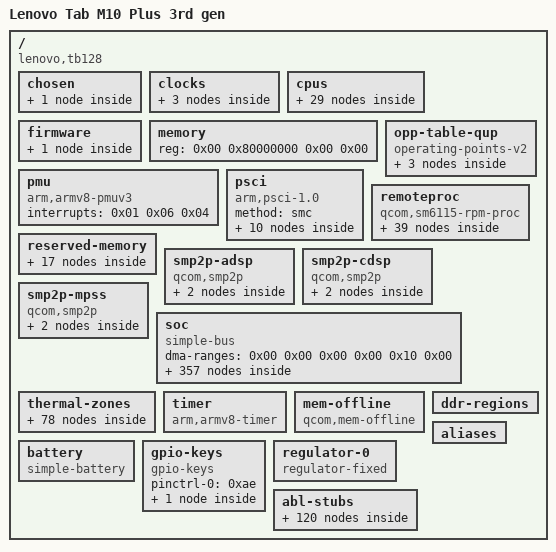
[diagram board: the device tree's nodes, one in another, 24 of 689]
/dts-v1/;

/ {
	interrupt-parent = <0x01>;
	#address-cells = <0x02>;
	#size-cells = <0x02>;
	model = "Lenovo Tab M10 Plus 3rd gen";
	compatible = "lenovo,tb128\0qcom,sm6225\0qcom,sm6115";
	chassis-type = "tablet";
	qcom,msm-id = <0x206 0x10000>;
	qcom,board-id = <0x10022 0x00>;
	qcom,pmic-id = <0x2d 0x00 0x00 0x00>;

	chosen {
		linux,initrd-start = <0x00 0x44986000>;
		linux,initrd-end = <0x00 0x456fe3fc>;
		kaslr-seed = <0x00 0x00>;
		bootargs = "root=/dev/sda18 rw rootwait noinitrd init=/sbin/init console=tty0 PMOS_NOSPLASH";
		#address-cells = <0x02>;
		#size-cells = <0x02>;
		ranges;
		stdout-path = "serial0:115200n8";

		framebuffer@5c000000 {
			compatible = "simple-framebuffer";
			reg = <0x00 0x5c000000 0x00 0x927c00>;
			width = <0x4b0>;
			height = <0x7d0>;
			stride = <0x12c0>;
			format = "a8r8g8b8";
			clocks = <0x02 0x4c>;
		};
	};

	clocks {

		xo-board {
			compatible = "fixed-clock";
			#clock-cells = <0x00>;
			clock-frequency = <0x124f800>;
			phandle = <0x25>;
		};

		sleep-clk {
			compatible = "fixed-clock";
			#clock-cells = <0x00>;
			clock-frequency = <0x7ffc>;
			phandle = <0x2c>;
		};

		usb3_phy_wrapper_gcc_usb30_pipe_clk {
			compatible = "fixed-clock";
			#clock-cells = <0x00>;
			clock-frequency = <0x3e8>;
			clock-output-names = "usb3_phy_wrapper_gcc_usb30_pipe_clk";
		};
	};

	cpus {
		#address-cells = <0x02>;
		#size-cells = <0x00>;

		cpu@0 {
			device_type = "cpu";
			compatible = "qcom,kryo260";
			reg = <0x00 0x00>;
			clocks = <0x03 0x00>;
			capacity-dmips-mhz = <0x400>;
			dynamic-power-coefficient = <0x64>;
			enable-method = "psci";
			next-level-cache = <0x04>;
			qcom,freq-domain = <0x03 0x00>;
			power-domains = <0x05>;
			power-domain-names = "psci";
			phandle = <0x0e>;

			l2-cache {
				compatible = "cache";
				cache-level = <0x02>;
				cache-unified;
				phandle = <0x04>;
			};
		};

		cpu@1 {
			device_type = "cpu";
			compatible = "qcom,kryo260";
			reg = <0x00 0x01>;
			clocks = <0x03 0x00>;
			capacity-dmips-mhz = <0x400>;
			dynamic-power-coefficient = <0x64>;
			enable-method = "psci";
			next-level-cache = <0x04>;
			qcom,freq-domain = <0x03 0x00>;
			power-domains = <0x06>;
			power-domain-names = "psci";
			phandle = <0x0f>;
		};

		cpu@2 {
			device_type = "cpu";
			compatible = "qcom,kryo260";
			reg = <0x00 0x02>;
			clocks = <0x03 0x00>;
			capacity-dmips-mhz = <0x400>;
			dynamic-power-coefficient = <0x64>;
			enable-method = "psci";
			next-level-cache = <0x04>;
			qcom,freq-domain = <0x03 0x00>;
			power-domains = <0x07>;
			power-domain-names = "psci";
			phandle = <0x10>;
		};

		cpu@3 {
			device_type = "cpu";
			compatible = "qcom,kryo260";
			reg = <0x00 0x03>;
			clocks = <0x03 0x00>;
			capacity-dmips-mhz = <0x400>;
			dynamic-power-coefficient = <0x64>;
			enable-method = "psci";
			next-level-cache = <0x04>;
			qcom,freq-domain = <0x03 0x00>;
			power-domains = <0x08>;
			power-domain-names = "psci";
			phandle = <0x11>;
		};

		cpu@100 {
			device_type = "cpu";
			compatible = "qcom,kryo260";
			reg = <0x00 0x100>;
			clocks = <0x03 0x01>;
			enable-method = "psci";
			capacity-dmips-mhz = <0x666>;
			dynamic-power-coefficient = <0x11a>;
			next-level-cache = <0x09>;
			qcom,freq-domain = <0x03 0x01>;
			power-domains = <0x0a>;
			power-domain-names = "psci";
			phandle = <0x12>;

			l2-cache {
				compatible = "cache";
				cache-level = <0x02>;
				cache-unified;
				phandle = <0x09>;
			};
		};

		cpu@101 {
			device_type = "cpu";
			compatible = "qcom,kryo260";
			reg = <0x00 0x101>;
			clocks = <0x03 0x01>;
			capacity-dmips-mhz = <0x666>;
			dynamic-power-coefficient = <0x11a>;
			enable-method = "psci";
			next-level-cache = <0x09>;
			qcom,freq-domain = <0x03 0x01>;
			power-domains = <0x0b>;
			power-domain-names = "psci";
			phandle = <0x13>;
		};

		cpu@102 {
			device_type = "cpu";
			compatible = "qcom,kryo260";
			reg = <0x00 0x102>;
			clocks = <0x03 0x01>;
			capacity-dmips-mhz = <0x666>;
			dynamic-power-coefficient = <0x11a>;
			enable-method = "psci";
			next-level-cache = <0x09>;
			qcom,freq-domain = <0x03 0x01>;
			power-domains = <0x0c>;
			power-domain-names = "psci";
			phandle = <0x14>;
		};

		cpu@103 {
			device_type = "cpu";
			compatible = "qcom,kryo260";
			reg = <0x00 0x103>;
			clocks = <0x03 0x01>;
			capacity-dmips-mhz = <0x666>;
			dynamic-power-coefficient = <0x11a>;
			enable-method = "psci";
			next-level-cache = <0x09>;
			qcom,freq-domain = <0x03 0x01>;
			power-domains = <0x0d>;
			power-domain-names = "psci";
			phandle = <0x15>;
		};

		cpu-map {

			cluster0 {

				core0 {
					cpu = <0x0e>;
				};

				core1 {
					cpu = <0x0f>;
				};

				core2 {
					cpu = <0x10>;
				};

				core3 {
					cpu = <0x11>;
				};
			};

			cluster1 {

				core0 {
					cpu = <0x12>;
				};

				core1 {
					cpu = <0x13>;
				};

				core2 {
					cpu = <0x14>;
				};

				core3 {
					cpu = <0x15>;
				};
			};
		};

		idle-states {
			entry-method = "psci";

			cpu-sleep-0-0 {
				compatible = "arm,idle-state";
				idle-state-name = "silver-rail-power-collapse";
				arm,psci-suspend-param = <0x40000003>;
				entry-latency-us = <0x122>;
				exit-latency-us = <0x178>;
				min-residency-us = <0x49e>;
				local-timer-stop;
				phandle = <0x1c>;
			};

			cpu-sleep-1-0 {
				compatible = "arm,idle-state";
				idle-state-name = "gold-rail-power-collapse";
				arm,psci-suspend-param = <0x40000003>;
				entry-latency-us = <0x129>;
				exit-latency-us = <0x144>;
				min-residency-us = <0x456>;
				local-timer-stop;
				phandle = <0x1e>;
			};
		};

		domain-idle-states {

			cluster-sleep-0-0 {
				compatible = "domain-idle-state";
				arm,psci-suspend-param = <0x40000022>;
				entry-latency-us = <0x168>;
				exit-latency-us = <0x1a5>;
				min-residency-us = <0x30e>;
				phandle = <0x1f>;
			};

			cluster-sleep-0-1 {
				compatible = "domain-idle-state";
				arm,psci-suspend-param = <0x41000044>;
				entry-latency-us = <0x320>;
				exit-latency-us = <0x846>;
				min-residency-us = <0x1cd0>;
				phandle = <0x20>;
			};

			cluster-sleep-1-0 {
				compatible = "domain-idle-state";
				arm,psci-suspend-param = <0x40000042>;
				entry-latency-us = <0x13a>;
				exit-latency-us = <0x159>;
				min-residency-us = <0x294>;
				phandle = <0x21>;
			};

			cluster-sleep-1-1 {
				compatible = "domain-idle-state";
				arm,psci-suspend-param = <0x41000044>;
				entry-latency-us = <0x280>;
				exit-latency-us = <0x676>;
				min-residency-us = <0x1f9e>;
				phandle = <0x22>;
			};
		};
	};

	firmware {

		scm {
			compatible = "qcom,scm-sm6115\0qcom,scm";
			#reset-cells = <0x01>;
			interconnects = <0x16 0x00 0x03 0x17 0x06 0x03>;
		};
	};

	memory {
		device_type = "memory";
		reg = <0x00 0x80000000 0x00 0x00>;
	};

	opp-table-qup {
		compatible = "operating-points-v2";
		phandle = <0x58>;

		opp-75000000 {
			opp-hz = <0x00 0x47868c0>;
			required-opps = <0x18>;
		};

		opp-100000000 {
			opp-hz = <0x00 0x5f5e100>;
			required-opps = <0x19>;
		};

		opp-128000000 {
			opp-hz = <0x00 0x7a12000>;
			required-opps = <0x1a>;
		};
	};

	pmu {
		compatible = "arm,armv8-pmuv3";
		interrupts = <0x01 0x06 0x04>;
	};

	psci {
		compatible = "arm,psci-1.0";
		method = "smc";

		power-domain-cpu0 {
			#power-domain-cells = <0x00>;
			power-domains = <0x1b>;
			domain-idle-states = <0x1c>;
			phandle = <0x05>;
		};

		power-domain-cpu1 {
			#power-domain-cells = <0x00>;
			power-domains = <0x1b>;
			domain-idle-states = <0x1c>;
			phandle = <0x06>;
		};

		power-domain-cpu2 {
			#power-domain-cells = <0x00>;
			power-domains = <0x1b>;
			domain-idle-states = <0x1c>;
			phandle = <0x07>;
		};

		power-domain-cpu3 {
			#power-domain-cells = <0x00>;
			power-domains = <0x1b>;
			domain-idle-states = <0x1c>;
			phandle = <0x08>;
		};

		power-domain-cpu4 {
			#power-domain-cells = <0x00>;
			power-domains = <0x1d>;
			domain-idle-states = <0x1e>;
			phandle = <0x0a>;
		};

		power-domain-cpu5 {
			#power-domain-cells = <0x00>;
			power-domains = <0x1d>;
			domain-idle-states = <0x1e>;
			phandle = <0x0b>;
		};

		power-domain-cpu6 {
			#power-domain-cells = <0x00>;
			power-domains = <0x1d>;
			domain-idle-states = <0x1e>;
			phandle = <0x0c>;
		};

		power-domain-cpu7 {
			#power-domain-cells = <0x00>;
			power-domains = <0x1d>;
			domain-idle-states = <0x1e>;
			phandle = <0x0d>;
		};

		power-domain-cpu-cluster0 {
			#power-domain-cells = <0x00>;
			domain-idle-states = <0x1f 0x20>;
			phandle = <0x1b>;
		};

		power-domain-cpu-cluster1 {
			#power-domain-cells = <0x00>;
			domain-idle-states = <0x21 0x22>;
			phandle = <0x1d>;
		};
	};

	remoteproc {
		compatible = "qcom,sm6115-rpm-proc\0qcom,rpm-proc";

		glink-edge {
			compatible = "qcom,glink-rpm";
			interrupts = <0x00 0xc2 0x01>;
			qcom,rpm-msg-ram = <0x23>;
			mboxes = <0x24 0x00>;

			rpm-requests {
				compatible = "qcom,rpm-sm6115\0qcom,glink-smd-rpm";
				qcom,glink-channels = "rpm_requests";

				clock-controller {
					compatible = "qcom,rpmcc-sm6115\0qcom,rpmcc";
					clocks = <0x25>;
					clock-names = "xo";
					#clock-cells = <0x01>;
					phandle = <0x2b>;
				};

				power-controller {
					compatible = "qcom,sm6115-rpmpd";
					#power-domain-cells = <0x01>;
					operating-points-v2 = <0x26>;
					phandle = <0x37>;

					opp-table {
						compatible = "operating-points-v2";
						phandle = <0x26>;

						opp1 {
							opp-level = <0x30>;
							phandle = <0x75>;
						};

						opp2 {
							opp-level = <0x40>;
							phandle = <0x18>;
						};

						opp3 {
							opp-level = <0x80>;
							phandle = <0x19>;
						};

						opp4 {
							opp-level = <0xc0>;
							phandle = <0x3a>;
						};

						opp5 {
							opp-level = <0x100>;
							phandle = <0x1a>;
						};

						opp6 {
							opp-level = <0x140>;
							phandle = <0x6d>;
						};

						opp7 {
							opp-level = <0x180>;
							phandle = <0x6e>;
						};

						opp8 {
							opp-level = <0x1a0>;
							phandle = <0x6f>;
						};
					};
				};

				regulators-0 {
					compatible = "qcom,rpm-pm6125-regulators";

					s6 {
						regulator-min-microvolt = <0x61a80>;
						regulator-max-microvolt = <0x15a6f8>;
					};

					s7 {
						regulator-min-microvolt = <0x17f0e8>;
						regulator-max-microvolt = <0x1f20c0>;
					};

					s8 {
						regulator-min-microvolt = <0x102ca0>;
						regulator-max-microvolt = <0x11da50>;
					};

					l1 {
						regulator-min-microvolt = <0xe7ef0>;
						regulator-max-microvolt = <0x118c30>;
					};

					l4 {
						regulator-min-microvolt = <0xafc80>;
						regulator-max-microvolt = <0x100590>;
						phandle = <0x2d>;
					};

					l5 {
						regulator-min-microvolt = <0x192580>;
						regulator-max-microvolt = <0x30d400>;
						regulator-allow-set-load;
						regulator-always-on;
						phandle = <0x3f>;
					};

					l6 {
						regulator-min-microvolt = <0x8b290>;
						regulator-max-microvolt = <0x9eb10>;
					};

					l7 {
						regulator-min-microvolt = <0x132a40>;
						regulator-max-microvolt = <0x132a40>;
						regulator-always-on;
					};

					l8 {
						regulator-min-microvolt = <0x61a80>;
						regulator-max-microvolt = <0xb1bc0>;
						phandle = <0xa7>;
					};

					l9 {
						regulator-min-microvolt = <0x1b7740>;
						regulator-max-microvolt = <0x1b7740>;
						regulator-always-on;
						regulator-boot-on;
						phandle = <0x4c>;
					};

					l10 {
						regulator-min-microvolt = <0x19f0a0>;
						regulator-max-microvolt = <0x1cfde0>;
					};

					l11 {
						regulator-min-microvolt = <0x19f0a0>;
						regulator-max-microvolt = <0x1dc130>;
						phandle = <0x42>;
					};

					l12 {
						regulator-min-microvolt = <0x18b820>;
						regulator-max-microvolt = <0x1e3660>;
						phandle = <0x2e>;
					};

					l13 {
						regulator-min-microvolt = <0x16f300>;
						regulator-max-microvolt = <0x1e8480>;
					};

					l14 {
						regulator-min-microvolt = <0x19f0a0>;
						regulator-max-microvolt = <0x1cfde0>;
					};

					l15 {
						regulator-min-microvolt = <0x2932e0>;
						regulator-max-microvolt = <0x3613c0>;
						phandle = <0x2f>;
					};

					l16 {
						regulator-min-microvolt = <0x19f0a0>;
						regulator-max-microvolt = <0x1cfde0>;
						phandle = <0x59>;
					};

					l17 {
						regulator-min-microvolt = <0x13e5c0>;
						regulator-max-microvolt = <0x13e5c0>;
						phandle = <0xa8>;
					};

					l18 {
						regulator-min-microvolt = <0x10c8e0>;
						regulator-max-microvolt = <0x13d620>;
						phandle = <0x43>;
					};

					l19 {
						regulator-min-microvolt = <0x18b820>;
						regulator-max-microvolt = <0x325aa0>;
					};

					l20 {
						regulator-min-microvolt = <0x18b820>;
						regulator-max-microvolt = <0x325aa0>;
					};

					l21 {
						regulator-min-microvolt = <0x186a00>;
						regulator-max-microvolt = <0x3613c0>;
					};

					l22 {
						regulator-min-microvolt = <0x2d0370>;
						regulator-max-microvolt = <0x325aa0>;
						regulator-allow-set-load;
						regulator-always-on;
						phandle = <0x3e>;
					};

					l23 {
						regulator-min-microvolt = <0x30d400>;
						regulator-max-microvolt = <0x33e140>;
						phandle = <0xa9>;
					};

					l24 {
						regulator-min-microvolt = <0x2932e0>;
						regulator-max-microvolt = <0x3613c0>;
						phandle = <0x41>;
					};
				};
			};
		};
	};

	reserved-memory {
		#address-cells = <0x02>;
		#size-cells = <0x02>;
		ranges;

		memory@45700000 {
			reg = <0x00 0x45700000 0x00 0x600000>;
			no-map;
		};

		memory@45e00000 {
			reg = <0x00 0x45e00000 0x00 0x140000>;
			no-map;
		};

		memory@45fff000 {
			reg = <0x00 0x45fff000 0x00 0x1000>;
			no-map;
		};

		memory@46000000 {
			compatible = "qcom,smem";
			reg = <0x00 0x46000000 0x00 0x200000>;
			no-map;
			hwlocks = <0x27 0x03>;
			qcom,rpm-msg-ram = <0x23>;
		};

		memory@46200000 {
			reg = <0x00 0x46200000 0x00 0x1e00000>;
			no-map;
		};

		memory@4ab00000 {
			reg = <0x00 0x4ab00000 0x00 0x6900000>;
			no-map;
			phandle = <0x7e>;
		};

		memory@51400000 {
			reg = <0x00 0x51400000 0x00 0x500000>;
			no-map;
		};

		memory@51900000 {
			reg = <0x00 0x51900000 0x00 0x100000>;
			no-map;
			phandle = <0xa6>;
		};

		memory@51a00000 {
			reg = <0x00 0x51a00000 0x00 0x1e00000>;
			no-map;
			phandle = <0xa4>;
		};

		memory@53800000 {
			reg = <0x00 0x53800000 0x00 0x1e00000>;
			no-map;
			phandle = <0xa1>;
		};

		memory@55600000 {
			reg = <0x00 0x55600000 0x00 0x10000>;
			no-map;
		};

		memory@55610000 {
			reg = <0x00 0x55610000 0x00 0x5000>;
			no-map;
		};

		memory@55615000 {
			reg = <0x00 0x55615000 0x00 0x2000>;
			no-map;
			phandle = <0x6c>;
		};

		splash_region@5c000000 {
			label = "cont_splash_region";
			reg = <0x00 0x5c000000 0x00 0xf00000>;
			no-map;
		};

		memory@5cf00000 {
			reg = <0x00 0x5cf00000 0x00 0x100000>;
			no-map;
		};

		memory@60000000 {
			reg = <0x00 0x60000000 0x00 0x3900000>;
			no-map;
		};

		memory@89b01000 {
			compatible = "qcom,rmtfs-mem";
			reg = <0x00 0x89b01000 0x00 0x300000>;
			no-map;
			qcom,client-id = <0x01>;
			qcom,vmid = <0x0f 0x2b>;
		};
	};

	smp2p-adsp {
		compatible = "qcom,smp2p";
		qcom,smem = <0x1bb 0x1ad>;
		interrupts = <0x00 0x117 0x01>;
		mboxes = <0x24 0x0a>;
		qcom,local-pid = <0x00>;
		qcom,remote-pid = <0x02>;

		master-kernel {
			qcom,entry-name = "master-kernel";
			#qcom,smem-state-cells = <0x01>;
			phandle = <0xa2>;
		};

		slave-kernel {
			qcom,entry-name = "slave-kernel";
			interrupt-controller;
			#interrupt-cells = <0x02>;
			phandle = <0xa0>;
		};
	};

	smp2p-cdsp {
		compatible = "qcom,smp2p";
		qcom,smem = <0x5e 0x1b0>;
		interrupts = <0x00 0x107 0x01>;
		mboxes = <0x24 0x1e>;
		qcom,local-pid = <0x00>;
		qcom,remote-pid = <0x05>;

		master-kernel {
			qcom,entry-name = "master-kernel";
			#qcom,smem-state-cells = <0x01>;
			phandle = <0xa5>;
		};

		slave-kernel {
			qcom,entry-name = "slave-kernel";
			interrupt-controller;
			#interrupt-cells = <0x02>;
			phandle = <0xa3>;
		};
	};

	smp2p-mpss {
		compatible = "qcom,smp2p";
		qcom,smem = <0x1b3 0x1ac>;
		interrupts = <0x00 0x46 0x01>;
		mboxes = <0x24 0x0e>;
		qcom,local-pid = <0x00>;
		qcom,remote-pid = <0x01>;

		master-kernel {
			qcom,entry-name = "master-kernel";
			#qcom,smem-state-cells = <0x01>;
			phandle = <0x7f>;
		};

		slave-kernel {
			qcom,entry-name = "slave-kernel";
			interrupt-controller;
			#interrupt-cells = <0x02>;
			phandle = <0x7d>;
		};
	};

	soc {
		compatible = "simple-bus";
		#address-cells = <0x02>;
		#size-cells = <0x02>;
		ranges = <0x00 0x00 0x00 0x00 0x10 0x00>;
		dma-ranges = <0x00 0x00 0x00 0x00 0x10 0x00>;

		hwlock@340000 {
			compatible = "qcom,tcsr-mutex";
			reg = <0x00 0x340000 0x00 0x20000>;
			#hwlock-cells = <0x01>;
			phandle = <0x27>;
		};

		syscon@3c0000 {
			compatible = "qcom,sm6115-tcsr\0syscon";
			reg = <0x00 0x3c0000 0x00 0x40000>;
			phandle = <0x32>;
		};

		pinctrl@500000 {
			compatible = "qcom,sm6115-tlmm";
			reg = <0x00 0x500000 0x00 0x400000 0x00 0x900000 0x00 0x400000 0x00 0xd00000 0x00 0x400000>;
			reg-names = "west\0south\0east";
			interrupts = <0x00 0xe3 0x04>;
			gpio-controller;
			gpio-ranges = <0x28 0x00 0x00 0x72>;
			#gpio-cells = <0x02>;
			interrupt-controller;
			#interrupt-cells = <0x02>;
			phandle = <0x28>;

			qup-i2c0-default-state {
				pins = "gpio0\0gpio1";
				function = "qup0";
				drive-strength = <0x02>;
				bias-pull-up;
				phandle = <0x45>;
			};

			qup-i2c1-default-state {
				pins = "gpio4\0gpio5";
				function = "qup1";
				drive-strength = <0x02>;
				bias-pull-up;
				phandle = <0x4e>;
			};

			qup-i2c2-default-state {
				pins = "gpio6\0gpio7";
				function = "qup2";
				drive-strength = <0x02>;
				bias-pull-up;
				phandle = <0x52>;
			};

			qup-i2c3-default-state {
				pins = "gpio8\0gpio9";
				function = "qup3";
				drive-strength = <0x02>;
				bias-pull-up;
				phandle = <0x56>;
			};

			qup-i2c4-default-state {
				pins = "gpio12\0gpio13";
				function = "qup4";
				drive-strength = <0x02>;
				bias-pull-up;
				phandle = <0x5a>;
			};

			qup-i2c5-default-state {
				pins = "gpio14\0gpio15";
				function = "qup5";
				drive-strength = <0x02>;
				bias-pull-up;
				phandle = <0x5e>;
			};

			qup-spi0-default-state {
				pins = "gpio0\0gpio1\0gpio2\0gpio3";
				function = "qup0";
				drive-strength = <0x02>;
				bias-pull-up;
				phandle = <0x47>;
			};

			qup-spi1-default-state {
				pins = "gpio4\0gpio5\0gpio69\0gpio70";
				function = "qup1";
				drive-strength = <0x02>;
				bias-pull-up;
				phandle = <0x50>;
			};

			qup-spi2-default-state {
				pins = "gpio6\0gpio7\0gpio71\0gpio80";
				function = "qup2";
				drive-strength = <0x02>;
				bias-pull-up;
				phandle = <0x55>;
			};

			qup-spi3-default-state {
				pins = "gpio8\0gpio9\0gpio10\0gpio11";
				function = "qup3";
				drive-strength = <0x02>;
				bias-pull-up;
				phandle = <0x57>;
			};

			qup-spi4-default-state {
				pins = "gpio12\0gpio13\0gpio96\0gpio97";
				function = "qup4";
				drive-strength = <0x02>;
				bias-pull-up;
				phandle = <0x5b>;
			};

			qup-spi5-default-state {
				pins = "gpio14\0gpio15\0gpio16\0gpio17";
				function = "qup5";
				drive-strength = <0x02>;
				bias-pull-up;
				phandle = <0x62>;
			};

			sdc1-on-state {

				clk-pins {
					pins = "sdc1_clk";
					bias-disable;
					drive-strength = <0x10>;
				};

				cmd-pins {
					pins = "sdc1_cmd";
					bias-pull-up;
					drive-strength = <0x0a>;
				};

				data-pins {
					pins = "sdc1_data";
					bias-pull-up;
					drive-strength = <0x0a>;
				};

				rclk-pins {
					pins = "sdc1_rclk";
					bias-pull-down;
				};
			};

			sdc1-off-state {

				clk-pins {
					pins = "sdc1_clk";
					bias-disable;
					drive-strength = <0x02>;
				};

				cmd-pins {
					pins = "sdc1_cmd";
					bias-pull-up;
					drive-strength = <0x02>;
				};

				data-pins {
					pins = "sdc1_data";
					bias-pull-up;
					drive-strength = <0x02>;
				};

				rclk-pins {
					pins = "sdc1_rclk";
					bias-pull-down;
				};
			};

			sdc2-on-state {
				phandle = <0x3b>;

				clk-pins {
					pins = "sdc2_clk";
					bias-disable;
					drive-strength = <0x10>;
				};

				cmd-pins {
					pins = "sdc2_cmd";
					bias-pull-up;
					drive-strength = <0x0a>;
				};

				data-pins {
					pins = "sdc2_data";
					bias-pull-up;
					drive-strength = <0x0a>;
				};

				cd-pins {
					pins = "gpio88";
					function = "gpio";
					drive-strength = <0x02>;
					bias-pull-up;
				};
			};

			sdc2-off-state {
				phandle = <0x3d>;

				clk-pins {
					pins = "sdc2_clk";
					bias-disable;
					drive-strength = <0x02>;
				};

				cmd-pins {
					pins = "sdc2_cmd";
					bias-pull-up;
					drive-strength = <0x02>;
				};

				data-pins {
					pins = "sdc2_data";
					bias-pull-up;
					drive-strength = <0x02>;
				};

				cd-pins {
					pins = "gpio88";
					function = "gpio";
					drive-strength = <0x02>;
					bias-disable;
				};
			};

			qup-uart4-active-state {
				pins = "gpio12\0gpio13";
				function = "qup4";
				drive-strength = <0x02>;
				bias-disable;
				phandle = <0x5c>;
			};

			qup-uart4-sleep-state {
				pins = "gpio12\0gpio13";
				function = "gpio";
				drive-strength = <0x02>;
				bias-pull-down;
				phandle = <0x5d>;
			};

			sdc2-gate-state {
				pins = "gpio93";
				function = "gpio";
				drive-strength = <0x02>;
				bias-pull-up;
				output-high;
				phandle = <0x3c>;
			};

			ts-reset-active-state {
				pins = "gpio86";
				function = "gpio";
				drive-strength = <0x10>;
				bias-pull-up;
				phandle = <0x49>;
			};

			ts-reset-suspend-state {
				pins = "gpio86";
				function = "gpio";
				drive-strength = <0x10>;
				bias-disable;
				output-high;
				phandle = <0x4b>;
			};

			ts-int-active-state {
				pins = "gpio80";
				function = "gpio";
				drive-strength = <0x10>;
				bias-pull-up;
				phandle = <0x48>;
			};

			ts-int-suspend-state {
				pins = "gpio80";
				function = "gpio";
				drive-strength = <0x10>;
				input-enable;
				bias-disable;
				phandle = <0x4a>;
			};

			te-active-state {
				pins = "gpio81";
				function = "mdp_vsync";
				drive-strength = <0x02>;
				bias-pull-down;
				phandle = <0x7a>;
			};

			dsi-active-state {
				pins = "gpio82";
				function = "gpio";
				drive-strength = <0x08>;
				bias-disable;
				phandle = <0x7b>;
			};

			charger-int-default-state {
				pins = "gpio65";
				function = "gpio";
				drive-strength = <0x02>;
				input-enable;
				bias-pull-up;
			};

			sy6974-en-state {
				pins = "gpio16";
				function = "gpio";
				drive-strength = <0x02>;
				bias-pull-up;
				phandle = <0x54>;
			};

			rt1715-int-default-state {
				pins = "gpio17";
				function = "gpio";
				drive-strength = <0x02>;
				bias-pull-up;
				phandle = <0x5f>;
			};

			rt1715-ldo-enable-state {
				pins = "gpio72";
				function = "gpio";
				drive-strength = <0x02>;
				bias-disable = <0x00>;
				output-high;
				phandle = <0x60>;
			};

			sy6974-int-default-state {
				pins = "gpio66";
				function = "gpio";
				drive-strength = <0x02>;
				input-enable;
				bias-pull-up;
				phandle = <0x53>;
			};

			pm8008-int-default-state {
				pins = "gpio25";
				function = "gpio";
				drive-strength = <0x02>;
				bias-disable;
			};

			usb-data-active-state {
				pins = "gpio112";
				function = "gpio";
				drive-strength = <0x02>;
				bias-disable;
				output-low;
				phandle = <0x63>;
			};
		};

		pinctrl@a7c0000 {
			compatible = "qcom,sm6115-lpass-lpi-pinctrl";
			reg = <0x00 0xa7c0000 0x00 0x20000 0x00 0xa950000 0x00 0x10000>;
			clocks = <0x29 0x67 0x01>;
			clock-names = "audio";
			gpio-controller;
			#gpio-cells = <0x02>;
			gpio-ranges = <0x2a 0x00 0x00 0x13>;
			phandle = <0x2a>;
		};

		clock-controller@1400000 {
			compatible = "qcom,gcc-sm6225";
			reg = <0x00 0x1400000 0x00 0x1f0000>;
			clocks = <0x2b 0x00 0x2c>;
			clock-names = "bi_tcxo\0sleep_clk";
			#clock-cells = <0x01>;
			#reset-cells = <0x01>;
			#power-domain-cells = <0x01>;
			phandle = <0x02>;
		};

		phy@1613000 {
			compatible = "qcom,sm6375-usb-hs-phy\0qcom,usb-snps-hs-7nm-phy";
			reg = <0x00 0x1613000 0x00 0x180>;
			#phy-cells = <0x00>;
			clocks = <0x02 0x11 0x2b 0x00>;
			clock-names = "cfg_ahb\0ref";
			resets = <0x02 0x00>;
			status = "okay";
			vdda-pll-supply = <0x2d>;
			vdda18-supply = <0x2e>;
			vdda33-supply = <0x2f>;
			phandle = <0x64>;
		};

		dma-controller@1b04000 {
			compatible = "qcom,bam-v1.7.4\0qcom,bam-v1.7.0";
			reg = <0x00 0x1b04000 0x00 0x24000>;
			interrupts = <0x00 0xf7 0x04>;
			clocks = <0x2b 0x46>;
			clock-names = "bam_clk";
			#dma-cells = <0x01>;
			qcom,ee = <0x00>;
			qcom,controlled-remotely;
			iommus = <0x30 0x92 0x00 0x30 0x94 0x11 0x30 0x96 0x11 0x30 0x98 0x01 0x30 0x9f 0x00>;
			phandle = <0x31>;
		};

		crypto@1b20000 {
			compatible = "qcom,sm6115-qce\0qcom,ipq4019-qce\0qcom,qce";
			reg = <0x00 0x1b20000 0x00 0x6000>;
			clocks = <0x2b 0x46>;
			clock-names = "core";
			dmas = <0x31 0x06 0x31 0x07>;
			dma-names = "rx\0tx";
			iommus = <0x30 0x92 0x00 0x30 0x94 0x11 0x30 0x96 0x11 0x30 0x98 0x01 0x30 0x9f 0x00>;
		};

		phy@1615000 {
			compatible = "qcom,sm6115-qmp-usb3-phy";
			reg = <0x00 0x1615000 0x00 0x1000>;
			clocks = <0x02 0x11 0x02 0x95 0x02 0x97 0x02 0x98>;
			clock-names = "cfg_ahb\0ref\0com_aux\0pipe";
			resets = <0x02 0x0b 0x02 0x0a>;
			reset-names = "phy\0phy_phy";
			#clock-cells = <0x00>;
			clock-output-names = "usb3_phy_pipe_clk_src";
			#phy-cells = <0x00>;
			orientation-switch;
			qcom,tcsr-reg = <0x32 0xb244>;
			status = "disabled";

			ports {
				#address-cells = <0x01>;
				#size-cells = <0x00>;

				port@0 {
					reg = <0x00>;

					endpoint {
					};
				};

				port@1 {
					reg = <0x01>;

					endpoint {
						remote-endpoint = <0x33>;
						phandle = <0x66>;
					};
				};
			};
		};

		interconnect@1880000 {
			compatible = "qcom,sm6115-snoc";
			reg = <0x00 0x1880000 0x00 0x5f080>;
			clocks = <0x02 0x7f 0x02 0x80 0x02 0x81 0x2b 0x44>;
			clock-names = "cpu_axi\0ufs_axi\0usb_axi\0ipa";
			#interconnect-cells = <0x02>;
			phandle = <0x16>;

			interconnect-clk {
				compatible = "qcom,sm6115-clk-virt";
				#interconnect-cells = <0x02>;
				phandle = <0x51>;
			};

			interconnect-mmrt {
				compatible = "qcom,sm6115-mmrt-virt";
				#interconnect-cells = <0x02>;
				phandle = <0x71>;
			};

			interconnect-mmnrt {
				compatible = "qcom,sm6115-mmnrt-virt";
				#interconnect-cells = <0x02>;
			};
		};

		interconnect@1900000 {
			compatible = "qcom,sm6115-cnoc";
			reg = <0x00 0x1900000 0x00 0x6200>;
			clocks = <0x02 0x47>;
			clock-names = "usb_axi";
			#interconnect-cells = <0x02>;
			phandle = <0x39>;
		};

		qfprom@1b40000 {
			compatible = "qcom,sm6115-qfprom\0qcom,qfprom";
			reg = <0x00 0x1b40000 0x00 0x7000>;
			#address-cells = <0x01>;
			#size-cells = <0x01>;

			adsp_variant@6011 {
				reg = <0x6011 0x01>;
				bits = <0x03 0x01>;
			};

			gpu-speed-bin@6006 {
				reg = <0x6006 0x02>;
				bits = <0x05 0x08>;
				phandle = <0x6b>;
			};

			feat_conf10@602c {
				reg = <0x602c 0x04>;
			};

			feat_conf11@6030 {
				reg = <0x6030 0x01>;
				bits = <0x00 0x08>;
			};

			gpu_gaming_bin@602d {
				reg = <0x602d 0x01>;
				bits = <0x05 0x01>;
			};

			stm@20f0 {
				reg = <0x20f0 0x04>;
			};

			feat_conf5@6018 {
				reg = <0x6018 0x04>;
			};
		};

		rng@1b53000 {
			compatible = "qcom,prng-ee";
			reg = <0x00 0x1b53000 0x00 0x1000>;
			clocks = <0x02 0x61>;
			clock-names = "core";
		};

		pmu@1b8e300 {
			compatible = "qcom,sm6115-cpu-bwmon\0qcom,sdm845-bwmon";
			reg = <0x00 0x1b8e300 0x00 0x600>;
			interrupts = <0x00 0x1a5 0x04>;
			operating-points-v2 = <0x34>;
			interconnects = <0x17 0x00 0x01 0x17 0x06 0x01>;

			opp-table {
				compatible = "operating-points-v2";
				phandle = <0x34>;

				opp-0 {
					opp-peak-kBps = "\0\f5";
				};

				opp-1 {
					opp-peak-kBps = <0x124f80>;
				};

				opp-2 {
					opp-peak-kBps = <0x1b86e0>;
				};

				opp-3 {
					opp-peak-kBps = <0x2162e0>;
				};

				opp-4 {
					opp-peak-kBps = <0x2990a0>;
				};

				opp-5 {
					opp-peak-kBps = <0x2ee000>;
				};

				opp-6 {
					opp-peak-kBps = <0x3e12a0>;
				};

				opp-7 {
					opp-peak-kBps = <0x5294a0>;
				};

				opp-8 {
					opp-peak-kBps = <0x5ee8e0>;
				};

				opp-9 {
					opp-peak-kBps = <0x6e1b80>;
				};
			};
		};

		spmi@1c40000 {
			compatible = "qcom,spmi-pmic-arb";
			reg = <0x00 0x1c40000 0x00 0x1100 0x00 0x1e00000 0x00 0x2000000 0x00 0x3e00000 0x00 0x100000 0x00 0x3f00000 0x00 0xa0000 0x00 0x1c0a000 0x00 0x26000>;
			reg-names = "core\0chnls\0obsrvr\0intr\0cnfg";
			interrupt-names = "periph_irq";
			interrupts = <0x00 0xb7 0x04>;
			qcom,ee = <0x00>;
			qcom,channel = <0x00>;
			#address-cells = <0x02>;
			#size-cells = <0x00>;
			interrupt-controller;
			#interrupt-cells = <0x04>;

			pmic@0 {
				compatible = "qcom,pm6125\0qcom,spmi-pmic";
				reg = <0x00 0x00>;
				#address-cells = <0x01>;
				#size-cells = <0x00>;

				pon@800 {
					compatible = "qcom,pm8998-pon";
					reg = <0x800>;
					mode-bootloader = <0x02>;
					mode-recovery = <0x01>;

					pwrkey {
						compatible = "qcom,pm8941-pwrkey";
						interrupts = <0x00 0x08 0x00 0x03>;
						debounce = <0x3d09>;
						linux,code = <0x74>;
						bias-pull-up;
						status = "okay";
					};

					resin {
						compatible = "qcom,pm8941-resin";
						interrupts = <0x00 0x08 0x01 0x03>;
						debounce = <0x3d09>;
						bias-pull-up;
						status = "okay";
						linux,code = <0x72>;
					};
				};

				temp-alarm@2400 {
					compatible = "qcom,spmi-temp-alarm";
					reg = <0x2400>;
					interrupts = <0x00 0x24 0x00 0x01>;
					io-channels = <0x35 0x06>;
					io-channel-names = "thermal";
					#thermal-sensor-cells = <0x00>;
					phandle = <0xad>;
				};

				adc@3100 {
					compatible = "qcom,spmi-adc5";
					reg = <0x3100>;
					#address-cells = <0x01>;
					#size-cells = <0x00>;
					interrupts = <0x00 0x31 0x00 0x01>;
					#io-channel-cells = <0x01>;
					phandle = <0x35>;

					channel@0 {
						reg = <0x00>;
						qcom,pre-scaling = <0x01 0x01>;
						label = "ref_gnd";
					};

					channel@1 {
						reg = <0x01>;
						qcom,pre-scaling = <0x01 0x01>;
						label = "vref_1p25";
					};

					channel@6 {
						reg = <0x06>;
						qcom,pre-scaling = <0x01 0x01>;
						label = "die_temp";
					};

					channel@83 {
						reg = <0x83>;
						qcom,pre-scaling = <0x01 0x03>;
						label = "vph_pwr";
					};

					channel@85 {
						reg = <0x85>;
						qcom,pre-scaling = <0x01 0x03>;
						label = "vcoin";
					};

					channel@4c {
						reg = <0x4c>;
						qcom,pre-scaling = <0x01 0x01>;
						qcom,hw-settle-time = <0xc8>;
						qcom,ratiometric;
						label = "xo_therm";
					};
				};

				adc-tm@3500 {
					compatible = "qcom,spmi-adc-tm5";
					reg = <0x3500>;
					interrupts = <0x00 0x35 0x00 0x01>;
					#address-cells = <0x01>;
					#size-cells = <0x00>;
					#thermal-sensor-cells = <0x01>;
					status = "disabled";
				};

				rtc@6000 {
					compatible = "qcom,pm8941-rtc";
					reg = <0x6000 0x6100>;
					reg-names = "rtc\0alarm";
					interrupts = <0x00 0x61 0x01 0x01>;
					status = "okay";
				};

				gpio@c000 {
					compatible = "qcom,pm6125-gpio\0qcom,spmi-gpio";
					reg = <0xc000>;
					gpio-controller;
					gpio-ranges = <0x36 0x00 0x00 0x09>;
					#gpio-cells = <0x02>;
					interrupt-controller;
					#interrupt-cells = <0x02>;
					phandle = <0x36>;

					vol-up-n-state {
						pins = "gpio5";
						function = "normal";
						power-source = <0x00>;
						bias-pull-up;
						input-enable;
						phandle = <0xae>;
					};
				};
			};

			pmic@1 {
				compatible = "qcom,pm6125\0qcom,spmi-pmic";
				reg = <0x01 0x00>;
			};
		};

		thermal-sensor@4411000 {
			compatible = "qcom,sm6115-tsens\0qcom,tsens-v2";
			reg = <0x00 0x4411000 0x00 0x1ff 0x00 0x4410000 0x00 0x08>;
			#qcom,sensors = <0x10>;
			interrupts = <0x00 0x113 0x04 0x00 0xbe 0x04>;
			interrupt-names = "uplow\0critical";
			#thermal-sensor-cells = <0x01>;
			phandle = <0xaa>;
		};

		interconnect@4480000 {
			compatible = "qcom,sm6115-bimc";
			reg = <0x00 0x4480000 0x00 0x80000>;
			#interconnect-cells = <0x02>;
			phandle = <0x17>;
		};

		sram@45f0000 {
			compatible = "qcom,rpm-msg-ram";
			reg = <0x00 0x45f0000 0x00 0x7000>;
			phandle = <0x23>;
		};

		sram@4690000 {
			compatible = "qcom,rpm-stats";
			reg = <0x00 0x4690000 0x00 0x10000>;
		};

		mmc@4744000 {
			compatible = "qcom,sm6115-sdhci\0qcom,sdhci-msm-v5";
			reg = <0x00 0x4744000 0x00 0x1000 0x00 0x4745000 0x00 0x1000 0x00 0x4748000 0x00 0x8000>;
			reg-names = "hc\0cqhci\0ice";
			interrupts = <0x00 0x15c 0x04 0x00 0x160 0x04>;
			interrupt-names = "hc_irq\0pwr_irq";
			clocks = <0x02 0x77 0x02 0x78 0x2b 0x00 0x02 0x7a>;
			clock-names = "iface\0core\0xo\0ice";
			resets = <0x02 0x02>;
			power-domains = <0x37 0x00>;
			operating-points-v2 = <0x38>;
			iommus = <0x30 0xc0 0x00>;
			interconnects = <0x16 0x0b 0x03 0x17 0x06 0x03 0x17 0x00 0x03 0x39 0x26 0x03>;
			interconnect-names = "sdhc-ddr\0cpu-sdhc";
			bus-width = <0x08>;
			status = "disabled";

			opp-table {
				compatible = "operating-points-v2";
				phandle = <0x38>;

				opp-100000000 {
					opp-hz = <0x00 0x5f5e100>;
					required-opps = <0x18>;
					opp-peak-kBps = <0x3d090 0x208c8>;
					opp-avg-kBps = <0x19000 0xfde8>;
				};

				opp-192000000 {
					opp-hz = <0x00 0xb71b000>;
					required-opps = <0x18>;
					opp-peak-kBps = <0xc3500 0x493e0>;
					opp-avg-kBps = <0x32000 0x30d40>;
				};

				opp-384000000 {
					opp-hz = <0x00 0x16e36000>;
					required-opps = <0x3a>;
					opp-peak-kBps = <0xc3500 0x493e0>;
					opp-avg-kBps = <0x32000 0x30d40>;
				};
			};
		};

		mmc@4784000 {
			compatible = "qcom,sm6225-sdhci\0qcom,sdhci-msm-v5";
			reg = <0x00 0x4784000 0x00 0x1000>;
			reg-names = "hc";
			interrupts = <0x00 0x15e 0x04 0x00 0x161 0x04>;
			interrupt-names = "hc_irq\0pwr_irq";
			clocks = <0x02 0x7c 0x02 0x7d 0x2b 0x00>;
			clock-names = "iface\0core\0xo";
			power-domains = <0x37 0x00>;
			iommus = <0x30 0xa0 0x00>;
			resets = <0x02 0x0c>;
			pinctrl-0 = <0x3b 0x3c>;
			pinctrl-1 = <0x3d>;
			pinctrl-names = "default\0sleep";
			qcom,dll-config = <0x7642c>;
			qcom,ddr-config = <0x80040873>;
			bus-width = <0x04>;
			status = "okay";
			cd-gpios = <0x28 0x58 0x00>;
			vmmc-supply = <0x3e>;
			vqmmc-supply = <0x3f>;
			no-sdio;
			no-mmc;
		};

		ufshc@4804000 {
			compatible = "qcom,sm6115-ufshc\0qcom,ufshc\0jedec,ufs-2.0";
			reg = <0x00 0x4804000 0x00 0x3000 0x00 0x4810000 0x00 0x8000>;
			reg-names = "std\0ice";
			interrupts = <0x00 0x164 0x04>;
			phys = <0x40>;
			phy-names = "ufsphy";
			lanes-per-direction = <0x02>;
			#reset-cells = <0x01>;
			resets = <0x02 0x03>;
			reset-names = "rst";
			power-domains = <0x02 0x01>;
			iommus = <0x30 0x100 0x00>;
			clocks = <0x02 0x84 0x02 0x80 0x02 0x83 0x02 0x8d 0x2b 0x00 0x02 0x8c 0x02 0x8a 0x02 0x8b 0x02 0x86>;
			clock-names = "core_clk\0bus_aggr_clk\0iface_clk\0core_clk_unipro\0ref_clk\0tx_lane0_sync_clk\0rx_lane0_sync_clk\0rx_lane1_sync_clk\0ice_core_clk";
			freq-table-hz = <0x2faf080 0xbebc200 0x00 0x00 0x00 0x00 0x23c3460 0x8f0d180 0x00 0x00 0x00 0x00 0x00 0x00 0x00 0x00 0x47868c0 0x11e1a300>;
			status = "okay";
			vcc-supply = <0x41>;
			vcc-max-microamp = <0x927c0>;
			vccq2-supply = <0x42>;
			vccq2-max-microamp = <0x927c0>;
			vdd-hba-supply = <0x43>;
			phandle = <0x44>;
		};

		phy@4807000 {
			compatible = "qcom,sm6225-qmp-ufs-phy";
			reg = <0x00 0x4807000 0x00 0x1000>;
			clocks = <0x2b 0x00 0x02 0x88 0x02 0x82>;
			clock-names = "ref\0ref_aux\0qref";
			power-domains = <0x02 0x01>;
			resets = <0x44 0x00>;
			reset-names = "ufsphy";
			#phy-cells = <0x00>;
			status = "okay";
			vdda-phy-supply = <0x2d>;
			vdda-pll-supply = <0x43>;
			phandle = <0x40>;
		};

		dma-controller@4a00000 {
			compatible = "qcom,sm6115-gpi-dma\0qcom,sm6350-gpi-dma";
			reg = <0x00 0x4a00000 0x00 0x60000>;
			interrupts = <0x00 0x14f 0x04 0x00 0x150 0x04 0x00 0x151 0x04 0x00 0x152 0x04 0x00 0x153 0x04 0x00 0x154 0x04 0x00 0x155 0x04 0x00 0x156 0x04 0x00 0x157 0x04 0x00 0x158 0x04>;
			dma-channels = <0x0a>;
			dma-channel-mask = <0x0f>;
			iommus = <0x30 0xf6 0x00>;
			#dma-cells = <0x03>;
			status = "disabled";
			phandle = <0x46>;
		};

		geniqup@4ac0000 {
			compatible = "qcom,geni-se-qup";
			reg = <0x00 0x4ac0000 0x00 0x2000>;
			clock-names = "m-ahb\0s-ahb";
			clocks = <0x02 0x75 0x02 0x76>;
			#address-cells = <0x02>;
			#size-cells = <0x02>;
			iommus = <0x30 0xe3 0x00>;
			ranges;
			status = "okay";

			i2c@4a80000 {
				compatible = "qcom,geni-i2c";
				reg = <0x00 0x4a80000 0x00 0x4000>;
				clock-names = "se";
				clocks = <0x02 0x69>;
				pinctrl-names = "default";
				pinctrl-0 = <0x45>;
				interrupts = <0x00 0x147 0x04>;
				dmas = <0x46 0x00 0x00 0x03 0x46 0x01 0x00 0x03>;
				dma-names = "tx\0rx";
				#address-cells = <0x01>;
				#size-cells = <0x00>;
				status = "disabled";
			};

			spi@4a80000 {
				compatible = "qcom,geni-spi";
				reg = <0x00 0x4a80000 0x00 0x4000>;
				clock-names = "se";
				clocks = <0x02 0x69>;
				pinctrl-names = "default";
				pinctrl-0 = <0x47>;
				interrupts = <0x00 0x147 0x04>;
				dmas = <0x46 0x00 0x00 0x01 0x46 0x01 0x00 0x01>;
				dma-names = "tx", "rx";
				spi-max-frequency = <0x2faf080>;
				#address-cells = <0x01>;
				#size-cells = <0x00>;
				status = "okay";
				clock-frequency = <0x927c00>;

				touchscreen@0 {
					status = "disabled";
					compatible = "himax,hxcommon";
					reg = <0x00>;
					spi-max-frequency = <0x989680>;
					spi-cpha;
					pinctrl-names = "default\0sleep";
					pinctrl-0 = <0x48 0x49>;
					pinctrl-1 = <0x4a 0x4b>;
					himax,panel-coords = <0x00 0x4b0 0x00 0x7d0>;
					himax,display-coords = <0x00 0x4b0 0x00 0x7d0>;
					himax,irq-gpio = <0x28 0x50 0x01>;
					himax,rst-gpio = <0x28 0x56 0x00>;
					vdd-supply = <0x4c>;
					report_type = <0x01>;
					panel = <0x4d>;
					touchscreen-inverted-x;
					touchscreen-inverted-y;
					himax,touch_info = <0x30 0x20 0x00 0x4b0 0x7d0 0x0a 0x00 0x01>;
				};

				touchscreen@1 {
					compatible = "novatek,nt36523-spi";
					reg = <0x01>;
					spi-max-frequency = <0x927c00>;
					pinctrl-0 = <0x48 0x49>;
					pinctrl-1 = <0x4a 0x4b>;
					pinctrl-names = "default\0sleep";
					reset-gpio = <0x28 0x56 0x00>;
					irq-gpio = <0x28 0x50 0x02>;
					novatek,swrst-n8-addr = <0x3f0fe>;
					firmware-name = "novatek_ts_fw.bin";
					panel = <0x4d>;
					touchscreen-inverted-x;
					touchscreen-inverted-y;
					novatek,pen-support;
					novatek,wgp-stylus;
					status = "okay";
				};
			};

			i2c@4a84000 {
				compatible = "qcom,geni-i2c";
				reg = <0x00 0x4a84000 0x00 0x4000>;
				clock-names = "se";
				clocks = <0x02 0x6b>;
				pinctrl-names = "default";
				pinctrl-0 = <0x4e>;
				interrupts = <0x00 0x148 0x04>;
				dmas = <0x46 0x00 0x01 0x03 0x46 0x01 0x01 0x03>;
				dma-names = "tx\0rx";
				#address-cells = <0x01>;
				#size-cells = <0x00>;
				status = "okay";

				fuel-gauge@55 {
					compatible = "ti,bq27541";
					reg = <0x55>;
					interrupts-extended = <0x28 0x1c 0x00>;
					monitored-battery = <0x4f>;
				};
			};

			spi@4a84000 {
				compatible = "qcom,geni-spi";
				reg = <0x00 0x4a84000 0x00 0x4000>;
				clock-names = "se";
				clocks = <0x02 0x6b>;
				pinctrl-names = "default";
				pinctrl-0 = <0x50>;
				interrupts = <0x00 0x148 0x04>;
				dmas = <0x46 0x00 0x01 0x01 0x46 0x01 0x01 0x01>;
				dma-names = "tx\0rx";
				interconnects = <0x51 0x00 0x03 0x51 0x01 0x03 0x17 0x00 0x03 0x39 0x24 0x03 0x16 0x08 0x03 0x17 0x06 0x03>;
				interconnect-names = "qup-core\0qup-config\0qup-memory";
				#address-cells = <0x01>;
				#size-cells = <0x00>;
				status = "disabled";
			};

			i2c@4a88000 {
				compatible = "qcom,geni-i2c";
				reg = <0x00 0x4a88000 0x00 0x4000>;
				clock-names = "se";
				clocks = <0x02 0x6d>;
				pinctrl-names = "default";
				pinctrl-0 = <0x52>;
				interrupts = <0x00 0x149 0x04>;
				dmas = <0x46 0x00 0x02 0x03 0x46 0x01 0x02 0x03>;
				dma-names = "tx\0rx";
				#address-cells = <0x01>;
				#size-cells = <0x00>;
				status = "okay";

				sy6974@6b {
					compatible = "silergy,sy6974";
					reg = <0x6b>;
					pinctrl-names = "default";
					pinctrl-0 = <0x53 0x54>;
					interrupt-parent = <0x28>;
					interrupts = <0x42 0x00>;
					sy,battery-regulation-voltage = <0x1060>;
					sy,termination-current = <0xf0>;
					sy,charge-current = <0x1f4>;
					sy,shutdown-current = <0x100>;
					sy,charge-voltage = <0x1150>;
					status = "disabled";
				};
			};

			spi@4a88000 {
				compatible = "qcom,geni-spi";
				reg = <0x00 0x4a88000 0x00 0x4000>;
				clock-names = "se";
				clocks = <0x02 0x6d>;
				pinctrl-names = "default";
				pinctrl-0 = <0x55>;
				interrupts = <0x00 0x149 0x04>;
				dmas = <0x46 0x00 0x02 0x01 0x46 0x01 0x02 0x01>;
				dma-names = "tx\0rx";
				interconnects = <0x51 0x00 0x03 0x51 0x01 0x03 0x17 0x00 0x03 0x39 0x24 0x03 0x16 0x08 0x03 0x17 0x06 0x03>;
				interconnect-names = "qup-core\0qup-config\0qup-memory";
				#address-cells = <0x01>;
				#size-cells = <0x00>;
				status = "disabled";
			};

			i2c@4a8c000 {
				compatible = "qcom,geni-i2c";
				reg = <0x00 0x4a8c000 0x00 0x4000>;
				clock-names = "se";
				clocks = <0x02 0x6f>;
				pinctrl-names = "default";
				pinctrl-0 = <0x56>;
				interrupts = <0x00 0x14a 0x04>;
				dmas = <0x46 0x00 0x03 0x03 0x46 0x01 0x03 0x03>;
				dma-names = "tx\0rx";
				interconnects = <0x51 0x00 0x03 0x51 0x01 0x03 0x17 0x00 0x03 0x39 0x24 0x03 0x16 0x08 0x03 0x17 0x06 0x03>;
				interconnect-names = "qup-core\0qup-config\0qup-memory";
				#address-cells = <0x01>;
				#size-cells = <0x00>;
				status = "disabled";
			};

			spi@4a8c000 {
				compatible = "qcom,geni-spi";
				reg = <0x00 0x4a8c000 0x00 0x4000>;
				clock-names = "se";
				clocks = <0x02 0x6f>;
				pinctrl-names = "default";
				pinctrl-0 = <0x57>;
				interrupts = <0x00 0x14a 0x04>;
				dmas = <0x46 0x00 0x03 0x01 0x46 0x01 0x03 0x01>;
				dma-names = "tx\0rx";
				interconnects = <0x51 0x00 0x03 0x51 0x01 0x03 0x17 0x00 0x03 0x39 0x24 0x03 0x16 0x08 0x03 0x17 0x06 0x03>;
				interconnect-names = "qup-core\0qup-config\0qup-memory";
				#address-cells = <0x01>;
				#size-cells = <0x00>;
				status = "disabled";
			};

			serial@4a8c000 {
				compatible = "qcom,geni-uart";
				reg = <0x00 0x4a8c000 0x00 0x4000>;
				interrupts-extended = <0x01 0x00 0x14a 0x04 0x28 0x0b 0x02>;
				clocks = <0x02 0x6f>;
				clock-names = "se";
				power-domains = <0x37 0x00>;
				operating-points-v2 = <0x58>;
				interconnects = <0x51 0x00 0x03 0x51 0x01 0x03 0x17 0x00 0x03 0x39 0x24 0x03>;
				interconnect-names = "qup-core\0qup-config";
				pinctrl-names = "default";
				pinctrl-0 = <0x57>;

				status = "okay";

				bluetooth {
					compatible = "qcom,wcn3990-bt";
					vddio-supply = <0x4c>;
					vddxo-supply = <0x59>;
					vddrf-supply = <0xa8>;
					vddch0-supply = <0xa9>;
					max-speed = <0x30d400>;
				};
			};

			i2c@4a90000 {
				compatible = "qcom,geni-i2c";
				reg = <0x00 0x4a90000 0x00 0x4000>;
				clock-names = "se";
				clocks = <0x02 0x71>;
				pinctrl-names = "default";
				pinctrl-0 = <0x5a>;
				interrupts = <0x00 0x14b 0x04>;
				dmas = <0x46 0x00 0x04 0x03 0x46 0x01 0x04 0x03>;
				dma-names = "tx\0rx";
				interconnects = <0x51 0x00 0x03 0x51 0x01 0x03 0x17 0x00 0x03 0x39 0x24 0x03 0x16 0x08 0x03 0x17 0x06 0x03>;
				interconnect-names = "qup-core\0qup-config\0qup-memory";
				#address-cells = <0x01>;
				#size-cells = <0x00>;
				status = "disabled";
			};

			spi@4a90000 {
				compatible = "qcom,geni-spi";
				reg = <0x00 0x4a90000 0x00 0x4000>;
				clock-names = "se";
				clocks = <0x02 0x71>;
				pinctrl-names = "default";
				pinctrl-0 = <0x5b>;
				interrupts = <0x00 0x14b 0x04>;
				dmas = <0x46 0x00 0x04 0x01 0x46 0x01 0x04 0x01>;
				dma-names = "tx\0rx";
				interconnects = <0x51 0x00 0x03 0x51 0x01 0x03 0x17 0x00 0x03 0x39 0x24 0x03 0x16 0x08 0x03 0x17 0x06 0x03>;
				interconnect-names = "qup-core\0qup-config\0qup-memory";
				#address-cells = <0x01>;
				#size-cells = <0x00>;
				status = "disabled";
			};

			serial@4a90000 {
				compatible = "qcom,geni-debug-uart";
				reg = <0x00 0x4a90000 0x00 0x4000>;
				clock-names = "se";
				clocks = <0x02 0x71>;
				interrupts = <0x00 0x14b 0x04>;
				interconnects = <0x51 0x00 0x03 0x51 0x01 0x03 0x17 0x00 0x03 0x39 0x24 0x03>;
				interconnect-names = "qup-core\0qup-config";
				status = "okay";
				pinctrl-names = "default\0sleep";
				pinctrl-0 = <0x5c>;
				pinctrl-1 = <0x5d>;
			};

			i2c@4a94000 {
				compatible = "qcom,geni-i2c";
				reg = <0x00 0x4a94000 0x00 0x4000>;
				clock-names = "se";
				clocks = <0x02 0x73>;
				pinctrl-names = "default";
				pinctrl-0 = <0x5e>;
				interrupts = <0x00 0x14c 0x04>;
				dmas = <0x46 0x00 0x05 0x03 0x46 0x01 0x05 0x03>;
				dma-names = "tx\0rx";
				#address-cells = <0x01>;
				#size-cells = <0x00>;
				status = "okay";

				rt1715@4e {
			status = "disabled";
					compatible = "richtek,rt1711h";
					reg = <0x4e>;
					interrupt-parent = <0x28>;
					interrupts = <0x11 0x08>;
					pinctrl-names = "default";
					pinctrl-0 = <0x5f 0x60>;

					connector {
						compatible = "usb-c-connector";
						label = "USB-C";
						data-role = "device";
						power-role = "sink";
						typec-power-opmode = "default";
						sink-pdos = <0x4019032>;
						op-sink-microwatt = <0x2625a0>;

						ports {
							#address-cells = <0x01>;
							#size-cells = <0x00>;

							port@0 {
								reg = <0x00>;

								endpoint {
									remote-endpoint = <0x61>;
									phandle = <0x65>;
								};
							};
						};
					};
				};
			};

			spi@4a94000 {
				compatible = "qcom,geni-spi";
				reg = <0x00 0x4a94000 0x00 0x4000>;
				clock-names = "se";
				clocks = <0x02 0x73>;
				pinctrl-names = "default";
				pinctrl-0 = <0x62>;
				interrupts = <0x00 0x14c 0x04>;
				dmas = <0x46 0x00 0x05 0x01 0x46 0x01 0x05 0x01>;
				dma-names = "tx\0rx";
				interconnects = <0x51 0x00 0x03 0x51 0x01 0x03 0x17 0x00 0x03 0x39 0x24 0x03 0x16 0x08 0x03 0x17 0x06 0x03>;
				interconnect-names = "qup-core\0qup-config\0qup-memory";
				#address-cells = <0x01>;
				#size-cells = <0x00>;
				status = "disabled";
			};
		};

		usb@4ef8800 {
			compatible = "qcom,sm6115-dwc3\0qcom,dwc3";
			reg = <0x00 0x4ef8800 0x00 0x400>;
			#address-cells = <0x02>;
			#size-cells = <0x02>;
			ranges;
			clocks = <0x02 0x47 0x02 0x8f 0x02 0x81 0x02 0x94 0x02 0x91 0x02 0x95>;
			clock-names = "cfg_noc\0core\0iface\0sleep\0mock_utmi\0xo";
			assigned-clocks = <0x02 0x91 0x02 0x8f>;
			assigned-clock-rates = <0x124f800 0x3f940ab>;
			interrupts = <0x00 0x12e 0x04 0x00 0x104 0x04 0x00 0xfe 0x04 0x00 0x1a6 0x04>;
			interrupt-names = "pwr_event\0qusb2_phy\0hs_phy_irq\0ss_phy_irq";
			resets = <0x02 0x04>;
			power-domains = <0x02 0x02>;
			interconnects = <0x16 0x0d 0x03 0x17 0x06 0x03 0x17 0x00 0x03 0x39 0x2c 0x03>;
			interconnect-names = "usb-ddr\0apps-usb";
			status = "okay";
			qcom,select-utmi-as-pipe-clk;
			pinctrl-names = "default";
			pinctrl-0 = <0x63>;

			usb@4e00000 {
				compatible = "snps,dwc3";
				reg = <0x00 0x4e00000 0x00 0xcd00>;
				interrupts = <0x00 0xff 0x04>;
				phys = <0x64>;
				phy-names = "usb2-phy";
				iommus = <0x30 0x120 0x00>;
				snps,dis_u2_susphy_quirk;
				snps,dis_enblslpm_quirk;
				snps,has-lpm-erratum;
				snps,hird-threshold = [10];
				snps,usb3_lpm_capable;
				snps,parkmode-disable-ss-quirk;
				usb-role-switch;
				dr_mode = "peripheral";
				maximum-speed = "high-speed";

				ports {
					#address-cells = <0x01>;
					#size-cells = <0x00>;

					port@0 {
						reg = <0x00>;

						endpoint {
							remote-endpoint = <0x65>;
							phandle = <0x61>;
						};
					};

					port@1 {
						reg = <0x01>;

						endpoint {
							remote-endpoint = <0x66>;
							phandle = <0x33>;
						};
					};
				};
			};
		};

		gpu@5900000 {
			compatible = "qcom,adreno-610.0\0qcom,adreno";
			reg = <0x00 0x5900000 0x00 0x40000>;
			reg-names = "kgsl_3d0_reg_memory";
			clocks = <0x67 0x0c 0x67 0x03 0x02 0x12 0x02 0x5a 0x67 0x06 0x67 0x09>;
			clock-names = "core\0iface\0mem_iface\0alt_mem_iface\0gmu\0xo";
			interrupts = <0x00 0xb1 0x04>;
			iommus = <0x68 0x00>;
			operating-points-v2 = <0x69>;
			power-domains = <0x37 0x00>;
			qcom,gmu = <0x6a>;
			nvmem-cells = <0x6b>;
			nvmem-cell-names = "speed_bin";
			#cooling-cells = <0x02>;
			status = "okay";
			phandle = <0xac>;

			zap-shader {
				memory-region = <0x6c>;
				firmware-name = "qcom/sm6225/LENOVO/TB128FU/a610_zap.mdt";
			};

			opp-table {
				compatible = "operating-points-v2";
				phandle = <0x69>;

				opp-320000000 {
					opp-hz = <0x00 0x1312d000>;
					required-opps = <0x18>;
					opp-supported-hw = <0x1f>;
				};

				opp-465000000 {
					opp-hz = <0x00 0x1bb75640>;
					required-opps = <0x19>;
					opp-supported-hw = <0x1f>;
				};

				opp-600000000 {
					opp-hz = <0x00 0x23c34600>;
					required-opps = <0x3a>;
					opp-supported-hw = <0x1f>;
				};

				opp-745000000 {
					opp-hz = <0x00 0x2c67cc40>;
					required-opps = <0x1a>;
					opp-supported-hw = <0x0f>;
				};

				opp-785000000 {
					opp-hz = <0x00 0x2eca2640>;
					required-opps = <0x1a>;
					opp-supported-hw = <0x0f>;
				};

				opp-820000000 {
					opp-hz = <0x00 0x30e03500>;
					required-opps = <0x6d>;
					opp-supported-hw = <0x07>;
				};

				opp-900000000 {
					opp-hz = <0x00 0x35a4e900>;
					required-opps = <0x6e>;
					opp-supported-hw = <0x07>;
				};

				opp-950000000 {
					opp-hz = <0x00 0x389fd980>;
					required-opps = <0x6f>;
					opp-supported-hw = <0x04>;
				};

				opp-980000000 {
					opp-hz = <0x00 0x3a699d00>;
					required-opps = <0x6f>;
					opp-supported-hw = <0x03>;
				};

				opp-1025000000 {
					opp-hz = <0x00 0x3d184240>;
					required-opps = <0x6e>;
					opp-supported-hw = <0x07>;
				};

				opp-1114800000 {
					opp-hz = <0x00 0x42727f80>;
					required-opps = <0x6f>;
					opp-supported-hw = <0x03>;
				};
			};
		};

		gmu@596a000 {
			compatible = "qcom,adreno-gmu-wrapper";
			reg = <0x00 0x596a000 0x00 0x30000>;
			reg-names = "gmu";
			power-domains = <0x67 0x10 0x67 0x00>;
			power-domain-names = "cx\0gx";
			phandle = <0x6a>;
		};

		clock-controller@5990000 {
			compatible = "qcom,sm6225-gpucc";
			reg = <0x00 0x5990000 0x00 0x9000>;
			clocks = <0x2b 0x00 0x02 0x57 0x02 0x58>;
			#clock-cells = <0x01>;
			#reset-cells = <0x01>;
			#power-domain-cells = <0x01>;
			phandle = <0x67>;
		};

		iommu@59a0000 {
			compatible = "qcom,sm6225-smmu-v2\0qcom,adreno-smmu\0qcom,smmu-v2";
			reg = <0x00 0x59a0000 0x00 0x10000>;
			#iommu-cells = <0x01>;
			#global-interrupts = <0x02>;
			interrupts = <0x00 0xa3 0x04 0x00 0xa7 0x04 0x00 0xa8 0x04 0x00 0xa9 0x04 0x00 0xaa 0x04 0x00 0xab 0x04 0x00 0xac 0x04 0x00 0xad 0x04 0x00 0xae 0x04>;
			clocks = <0x67 0x03 0x02 0x5a 0x02 0x5b>;
			clock-names = "ahb\0bus\0iface";
			power-domains = <0x67 0x10>;
			phandle = <0x68>;
		};

		display-subsystem@5e00000 {
			compatible = "qcom,sm6225-mdss";
			reg = <0x00 0x5e00000 0x00 0x1000>;
			reg-names = "mdss";
			power-domains = <0x70 0x00>;
			clocks = <0x02 0x49 0x02 0x4c 0x70 0x09>;
			interrupts = <0x00 0xba 0x04>;
			interrupt-controller;
			#interrupt-cells = <0x01>;
			interconnects = <0x71 0x01 0x03 0x17 0x06 0x03 0x17 0x00 0x03 0x39 0x10 0x03>;
			interconnect-names = "mdp0-mem\0cpu-cfg";
			iommus = <0x30 0x420 0x02 0x30 0x421 0x00>;
			#address-cells = <0x02>;
			#size-cells = <0x02>;
			ranges;
			status = "okay";
			phandle = <0x73>;

			display-controller@5e01000 {
				compatible = "qcom,sm6375-dpu";
				reg = <0x00 0x5e01000 0x00 0x8f000 0x00 0x5eb0000 0x00 0x2008>;
				reg-names = "mdp\0vbif";
				clocks = <0x02 0x4c 0x70 0x01 0x70 0x0f 0x70 0x0b 0x70 0x09 0x70 0x13 0x02 0x4e>;
				clock-names = "bus\0iface\0rot\0lut\0core\0vsync\0throttle";
				assigned-clocks = <0x70 0x13>;
				assigned-clock-rates = <0x124f800>;
				operating-points-v2 = <0x72>;
				power-domains = <0x37 0x00>;
				interrupt-parent = <0x73>;
				interrupts = <0x00>;

				ports {
					#address-cells = <0x01>;
					#size-cells = <0x00>;

					port@0 {
						reg = <0x00>;

						endpoint {
							remote-endpoint = <0x74>;
							phandle = <0x78>;
						};
					};
				};

				opp-table {
					compatible = "operating-points-v2";
					phandle = <0x72>;
					opp-384000000 {
						opp-hz = <0x00 0x16e36000>;
						required-opps = <0x1a>;
					};

				};
			};

			dsi@5e94000 {
				compatible = "qcom,sm6115-dsi-ctrl\0qcom,mdss-dsi-ctrl";
				reg = <0x00 0x5e94000 0x00 0x400>;
				reg-names = "dsi_ctrl";
				interrupt-parent = <0x73>;
				interrupts = <0x04>;
				clocks = <0x70 0x03 0x70 0x06 0x70 0x0d 0x70 0x07 0x70 0x01 0x02 0x4c>;
				clock-names = "byte\0byte_intf\0pixel\0core\0iface\0bus";
				assigned-clocks = <0x70 0x04 0x70 0x0e>;
				assigned-clock-parents = <0x76 0x00 0x76 0x01>;
				operating-points-v2 = <0x77>;
				power-domains = <0x37 0x00>;
				phys = <0x76>;
				#address-cells = <0x01>;
				#size-cells = <0x00>;
				status = "okay";
				vdda-supply = <0x43>;

				ports {
					#address-cells = <0x01>;
					#size-cells = <0x00>;

					port@0 {
						reg = <0x00>;

						endpoint {
							remote-endpoint = <0x78>;
							phandle = <0x74>;
						};
					};

					port@1 {
						reg = <0x01>;

						endpoint {
							data-lanes = <0x00 0x01 0x02 0x03>;
							remote-endpoint = <0x79>;
							phandle = <0x7c>;
						};
					};
				};

				opp-table {
					compatible = "operating-points-v2";
					phandle = <0x77>;

					opp-187500000 {
						opp-hz = <0x00 0xb2d05e0>;
						required-opps = <0x18>;
					};

					opp-300000000 {
						opp-hz = <0x00 0x11e1a300>;
						required-opps = <0x19>;
					};

					opp-358000000 {
						opp-hz = <0x00 0x1556a580>;
						required-opps = <0x3a>;
					};
				};

				panel@0 {
					compatible = "lenovo,p255-inx";
					reg = <0x00>;
					pinctrl-names = "default";
					pinctrl-0 = <0x7a 0x7b>;
					rotation = <0xb4>;
					enable-gpios = <0x28 0x52 0x00>;
					pp1800-supply = <0x4c>;
					phandle = <0x4d>;

					port {

						endpoint {
							remote-endpoint = <0x7c>;
							phandle = <0x79>;
						};
					};
				};
			};

			phy@5e94400 {
				compatible = "qcom,sm6375-dsi-phy-7nm";
				reg = <0x00 0x5e94400 0x00 0x200 0x00 0x5e94600 0x00 0x280 0x00 0x5e94900 0x00 0x264>;
				reg-names = "dsi_phy\0dsi_phy_lane\0dsi_pll";
				#clock-cells = <0x01>;
				#phy-cells = <0x00>;
				clocks = <0x70 0x01 0x2b 0x00>;
				clock-names = "iface\0ref";
				status = "okay";
				phandle = <0x76>;
			};
		};

		clock-controller@5f00000 {
			status = "okay";
			compatible = "qcom,sm6225-dispcc";
			reg = <0x00 0x5f00000 0x00 0x20000>;
			clocks = <0x2b 0x00 0x2c 0x76 0x00 0x76 0x01 0x02 0x4b>;
			#clock-cells = <0x01>;
			#reset-cells = <0x01>;
			#power-domain-cells = <0x01>;
			phandle = <0x70>;
		};

		remoteproc@6080000 {
			compatible = "qcom,sm6115-mpss-pas";
			reg = <0x00 0x6080000 0x00 0x10000>;
			interrupts-extended = <0x01 0x00 0x133 0x01 0x7d 0x00 0x01 0x7d 0x01 0x01 0x7d 0x02 0x01 0x7d 0x03 0x01 0x7d 0x07 0x01>;
			interrupt-names = "wdog\0fatal\0ready\0handover\0stop-ack\0shutdown-ack";
			clocks = <0x2b 0x00>;
			clock-names = "xo";
			power-domains = <0x37 0x00>;
			memory-region = <0x7e>;
			qcom,smem-states = <0x7f 0x00>;
			qcom,smem-state-names = "stop";
			status = "okay";
			firmware-name = "qcom/sm6225/LENOVO/TB128FU/modem.mbn";

			glink-edge {
				interrupts = <0x00 0x44 0x01>;
				label = "mpss";
				qcom,remote-pid = <0x01>;
				mboxes = <0x24 0x0c>;
			};
		};

		stm@8002000 {
			compatible = "arm,coresight-stm\0arm,primecell";
			reg = <0x00 0x8002000 0x00 0x1000 0x00 0xe280000 0x00 0x180000>;
			reg-names = "stm-base\0stm-stimulus-base";
			clocks = <0x2b 0x08>;
			clock-names = "apb_pclk";
			status = "disabled";

			out-ports {

				port {

					endpoint {
						remote-endpoint = <0x80>;
						phandle = <0x87>;
					};
				};
			};
		};

		cti@8010000 {
			compatible = "arm,coresight-cti\0arm,primecell";
			reg = <0x00 0x8010000 0x00 0x1000>;
			clocks = <0x2b 0x08>;
			clock-names = "apb_pclk";
			status = "disabled";
		};

		cti@8011000 {
			compatible = "arm,coresight-cti\0arm,primecell";
			reg = <0x00 0x8011000 0x00 0x1000>;
			clocks = <0x2b 0x08>;
			clock-names = "apb_pclk";
			status = "disabled";
		};

		cti@8012000 {
			compatible = "arm,coresight-cti\0arm,primecell";
			reg = <0x00 0x8012000 0x00 0x1000>;
			clocks = <0x2b 0x08>;
			clock-names = "apb_pclk";
			status = "disabled";
		};

		cti@8013000 {
			compatible = "arm,coresight-cti\0arm,primecell";
			reg = <0x00 0x8013000 0x00 0x1000>;
			clocks = <0x2b 0x08>;
			clock-names = "apb_pclk";
			status = "disabled";
		};

		cti@8014000 {
			compatible = "arm,coresight-cti\0arm,primecell";
			reg = <0x00 0x8014000 0x00 0x1000>;
			clocks = <0x2b 0x08>;
			clock-names = "apb_pclk";
			status = "disabled";
		};

		cti@8015000 {
			compatible = "arm,coresight-cti\0arm,primecell";
			reg = <0x00 0x8015000 0x00 0x1000>;
			clocks = <0x2b 0x08>;
			clock-names = "apb_pclk";
			status = "disabled";
		};

		cti@8016000 {
			compatible = "arm,coresight-cti\0arm,primecell";
			reg = <0x00 0x8016000 0x00 0x1000>;
			clocks = <0x2b 0x08>;
			clock-names = "apb_pclk";
			status = "disabled";
		};

		cti@8017000 {
			compatible = "arm,coresight-cti\0arm,primecell";
			reg = <0x00 0x8017000 0x00 0x1000>;
			clocks = <0x2b 0x08>;
			clock-names = "apb_pclk";
			status = "disabled";
		};

		cti@8018000 {
			compatible = "arm,coresight-cti\0arm,primecell";
			reg = <0x00 0x8018000 0x00 0x1000>;
			clocks = <0x2b 0x08>;
			clock-names = "apb_pclk";
			status = "disabled";
		};

		cti@8019000 {
			compatible = "arm,coresight-cti\0arm,primecell";
			reg = <0x00 0x8019000 0x00 0x1000>;
			clocks = <0x2b 0x08>;
			clock-names = "apb_pclk";
			status = "disabled";
		};

		cti@801a000 {
			compatible = "arm,coresight-cti\0arm,primecell";
			reg = <0x00 0x801a000 0x00 0x1000>;
			clocks = <0x2b 0x08>;
			clock-names = "apb_pclk";
			status = "disabled";
		};

		cti@801b000 {
			compatible = "arm,coresight-cti\0arm,primecell";
			reg = <0x00 0x801b000 0x00 0x1000>;
			clocks = <0x2b 0x08>;
			clock-names = "apb_pclk";
			status = "disabled";
		};

		cti@801c000 {
			compatible = "arm,coresight-cti\0arm,primecell";
			reg = <0x00 0x801c000 0x00 0x1000>;
			clocks = <0x2b 0x08>;
			clock-names = "apb_pclk";
			status = "disabled";
		};

		cti@801d000 {
			compatible = "arm,coresight-cti\0arm,primecell";
			reg = <0x00 0x801d000 0x00 0x1000>;
			clocks = <0x2b 0x08>;
			clock-names = "apb_pclk";
			status = "disabled";
		};

		cti@801e000 {
			compatible = "arm,coresight-cti\0arm,primecell";
			reg = <0x00 0x801e000 0x00 0x1000>;
			clocks = <0x2b 0x08>;
			clock-names = "apb_pclk";
			status = "disabled";
		};

		cti@801f000 {
			compatible = "arm,coresight-cti\0arm,primecell";
			reg = <0x00 0x801f000 0x00 0x1000>;
			clocks = <0x2b 0x08>;
			clock-names = "apb_pclk";
			status = "disabled";
		};

		replicator@8046000 {
			compatible = "arm,coresight-dynamic-replicator\0arm,primecell";
			reg = <0x00 0x8046000 0x00 0x1000>;
			clocks = <0x2b 0x08>;
			clock-names = "apb_pclk";
			status = "disabled";

			out-ports {

				port {

					endpoint {
						remote-endpoint = <0x81>;
						phandle = <0x85>;
					};
				};
			};

			in-ports {

				port {

					endpoint {
						remote-endpoint = <0x82>;
						phandle = <0x84>;
					};
				};
			};
		};

		etf@8047000 {
			compatible = "arm,coresight-tmc\0arm,primecell";
			reg = <0x00 0x8047000 0x00 0x1000>;
			clocks = <0x2b 0x08>;
			clock-names = "apb_pclk";
			status = "disabled";

			in-ports {

				port {

					endpoint {
						remote-endpoint = <0x83>;
						phandle = <0x8a>;
					};
				};
			};

			out-ports {

				port {

					endpoint {
						remote-endpoint = <0x84>;
						phandle = <0x82>;
					};
				};
			};
		};

		etr@8048000 {
			compatible = "arm,coresight-tmc\0arm,primecell";
			reg = <0x00 0x8048000 0x00 0x1000>;
			clocks = <0x2b 0x08>;
			clock-names = "apb_pclk";
			status = "disabled";

			in-ports {

				port {

					endpoint {
						remote-endpoint = <0x85>;
						phandle = <0x81>;
					};
				};
			};
		};

		funnel@8041000 {
			compatible = "arm,coresight-dynamic-funnel\0arm,primecell";
			reg = <0x00 0x8041000 0x00 0x1000>;
			clocks = <0x2b 0x08>;
			clock-names = "apb_pclk";
			status = "disabled";

			out-ports {

				port {

					endpoint {
						remote-endpoint = <0x86>;
						phandle = <0x8b>;
					};
				};
			};

			in-ports {

				port {

					endpoint {
						remote-endpoint = <0x87>;
						phandle = <0x80>;
					};
				};
			};
		};

		funnel@8042000 {
			compatible = "arm,coresight-dynamic-funnel\0arm,primecell";
			reg = <0x00 0x8042000 0x00 0x1000>;
			clocks = <0x2b 0x08>;
			clock-names = "apb_pclk";
			status = "disabled";

			out-ports {

				port {

					endpoint {
						remote-endpoint = <0x88>;
						phandle = <0x8c>;
					};
				};
			};

			in-ports {

				port {

					endpoint {
						remote-endpoint = <0x89>;
						phandle = <0x9e>;
					};
				};
			};
		};

		funnel@8045000 {
			compatible = "arm,coresight-dynamic-funnel\0arm,primecell";
			reg = <0x00 0x8045000 0x00 0x1000>;
			clocks = <0x2b 0x08>;
			clock-names = "apb_pclk";
			status = "disabled";

			out-ports {

				port {

					endpoint {
						remote-endpoint = <0x8a>;
						phandle = <0x83>;
					};
				};
			};

			in-ports {
				#address-cells = <0x01>;
				#size-cells = <0x00>;

				port@0 {
					reg = <0x00>;

					endpoint {
						remote-endpoint = <0x8b>;
						phandle = <0x86>;
					};
				};

				port@1 {
					reg = <0x01>;

					endpoint {
						remote-endpoint = <0x8c>;
						phandle = <0x88>;
					};
				};
			};
		};

		etm@9040000 {
			compatible = "arm,coresight-etm4x\0arm,primecell";
			reg = <0x00 0x9040000 0x00 0x1000>;
			clocks = <0x2b 0x08>;
			clock-names = "apb_pclk";
			arm,coresight-loses-context-with-cpu;
			cpu = <0x0e>;
			status = "disabled";

			out-ports {

				port {

					endpoint {
						remote-endpoint = <0x8d>;
						phandle = <0x96>;
					};
				};
			};
		};

		etm@9140000 {
			compatible = "arm,coresight-etm4x\0arm,primecell";
			reg = <0x00 0x9140000 0x00 0x1000>;
			clocks = <0x2b 0x08>;
			clock-names = "apb_pclk";
			arm,coresight-loses-context-with-cpu;
			cpu = <0x0f>;
			status = "disabled";

			out-ports {

				port {

					endpoint {
						remote-endpoint = <0x8e>;
						phandle = <0x97>;
					};
				};
			};
		};

		etm@9240000 {
			compatible = "arm,coresight-etm4x\0arm,primecell";
			reg = <0x00 0x9240000 0x00 0x1000>;
			clocks = <0x2b 0x08>;
			clock-names = "apb_pclk";
			arm,coresight-loses-context-with-cpu;
			cpu = <0x10>;
			status = "disabled";

			out-ports {

				port {

					endpoint {
						remote-endpoint = <0x8f>;
						phandle = <0x98>;
					};
				};
			};
		};

		etm@9340000 {
			compatible = "arm,coresight-etm4x\0arm,primecell";
			reg = <0x00 0x9340000 0x00 0x1000>;
			clocks = <0x2b 0x08>;
			clock-names = "apb_pclk";
			arm,coresight-loses-context-with-cpu;
			cpu = <0x11>;
			status = "disabled";

			out-ports {

				port {

					endpoint {
						remote-endpoint = <0x90>;
						phandle = <0x99>;
					};
				};
			};
		};

		etm@9440000 {
			compatible = "arm,coresight-etm4x\0arm,primecell";
			reg = <0x00 0x9440000 0x00 0x1000>;
			clocks = <0x2b 0x08>;
			clock-names = "apb_pclk";
			arm,coresight-loses-context-with-cpu;
			cpu = <0x12>;
			status = "disabled";

			out-ports {

				port {

					endpoint {
						remote-endpoint = <0x91>;
						phandle = <0x9a>;
					};
				};
			};
		};

		etm@9540000 {
			compatible = "arm,coresight-etm4x\0arm,primecell";
			reg = <0x00 0x9540000 0x00 0x1000>;
			clocks = <0x2b 0x08>;
			clock-names = "apb_pclk";
			arm,coresight-loses-context-with-cpu;
			cpu = <0x13>;
			status = "disabled";

			out-ports {

				port {

					endpoint {
						remote-endpoint = <0x92>;
						phandle = <0x9b>;
					};
				};
			};
		};

		etm@9640000 {
			compatible = "arm,coresight-etm4x\0arm,primecell";
			reg = <0x00 0x9640000 0x00 0x1000>;
			clocks = <0x2b 0x08>;
			clock-names = "apb_pclk";
			arm,coresight-loses-context-with-cpu;
			cpu = <0x14>;
			status = "disabled";

			out-ports {

				port {

					endpoint {
						remote-endpoint = <0x93>;
						phandle = <0x9c>;
					};
				};
			};
		};

		etm@9740000 {
			compatible = "arm,coresight-etm4x\0arm,primecell";
			reg = <0x00 0x9740000 0x00 0x1000>;
			clocks = <0x2b 0x08>;
			clock-names = "apb_pclk";
			arm,coresight-loses-context-with-cpu;
			cpu = <0x15>;
			status = "disabled";

			out-ports {

				port {

					endpoint {
						remote-endpoint = <0x94>;
						phandle = <0x9d>;
					};
				};
			};
		};

		funnel@9800000 {
			compatible = "arm,coresight-dynamic-funnel\0arm,primecell";
			reg = <0x00 0x9800000 0x00 0x1000>;
			clocks = <0x2b 0x08>;
			clock-names = "apb_pclk";
			status = "disabled";

			out-ports {

				port {

					endpoint {
						remote-endpoint = <0x95>;
						phandle = <0x9f>;
					};
				};
			};

			in-ports {
				#address-cells = <0x01>;
				#size-cells = <0x00>;

				port@0 {
					reg = <0x00>;

					endpoint {
						remote-endpoint = <0x96>;
						phandle = <0x8d>;
					};
				};

				port@1 {
					reg = <0x01>;

					endpoint {
						remote-endpoint = <0x97>;
						phandle = <0x8e>;
					};
				};

				port@2 {
					reg = <0x02>;

					endpoint {
						remote-endpoint = <0x98>;
						phandle = <0x8f>;
					};
				};

				port@3 {
					reg = <0x03>;

					endpoint {
						remote-endpoint = <0x99>;
						phandle = <0x90>;
					};
				};

				port@4 {
					reg = <0x04>;

					endpoint {
						remote-endpoint = <0x9a>;
						phandle = <0x91>;
					};
				};

				port@5 {
					reg = <0x05>;

					endpoint {
						remote-endpoint = <0x9b>;
						phandle = <0x92>;
					};
				};

				port@6 {
					reg = <0x06>;

					endpoint {
						remote-endpoint = <0x9c>;
						phandle = <0x93>;
					};
				};

				port@7 {
					reg = <0x07>;

					endpoint {
						remote-endpoint = <0x9d>;
						phandle = <0x94>;
					};
				};
			};
		};

		funnel@9810000 {
			compatible = "arm,coresight-dynamic-funnel\0arm,primecell";
			reg = <0x00 0x9810000 0x00 0x1000>;
			clocks = <0x2b 0x08>;
			clock-names = "apb_pclk";
			status = "disabled";

			out-ports {

				port {

					endpoint {
						remote-endpoint = <0x9e>;
						phandle = <0x89>;
					};
				};
			};

			in-ports {

				port {

					endpoint {
						remote-endpoint = <0x9f>;
						phandle = <0x95>;
					};
				};
			};
		};

		remoteproc@a400000 {
			compatible = "qcom,sm6115-adsp-pas";
			reg = <0x00 0xa400000 0x00 0x4040>;
			interrupts-extended = <0x01 0x00 0x11a 0x01 0xa0 0x00 0x01 0xa0 0x01 0x01 0xa0 0x02 0x01 0xa0 0x03 0x01>;
			interrupt-names = "wdog\0fatal\0ready\0handover\0stop-ack";
			clocks = <0x2b 0x00>;
			clock-names = "xo";
			power-domains = <0x37 0x06 0x37 0x07>;
			memory-region = <0xa1>;
			qcom,smem-states = <0xa2 0x00>;
			qcom,smem-state-names = "stop";
			status = "okay";
			firmware-name = "qcom/sm6225/LENOVO/TB128FU/adsp.mbn";

			glink-edge {
				interrupts = <0x00 0x115 0x01>;
				label = "lpass";
				qcom,remote-pid = <0x02>;
				mboxes = <0x24 0x08>;

				apr {
					compatible = "qcom,apr-v2";
					qcom,glink-channels = "apr_audio_svc";
					qcom,domain = <0x04>;
					#address-cells = <0x01>;
					#size-cells = <0x00>;

					service@3 {
						reg = <0x03>;
						compatible = "qcom,q6core";
						qcom,protection-domain = "avs/audio\0msm/adsp/audio_pd";
					};

					service@4 {
						compatible = "qcom,q6afe";
						reg = <0x04>;
						qcom,protection-domain = "avs/audio\0msm/adsp/audio_pd";

						dais {
							compatible = "qcom,q6afe-dais";
							#address-cells = <0x01>;
							#size-cells = <0x00>;
							#sound-dai-cells = <0x01>;
						};

						clock-controller {
							compatible = "qcom,q6afe-clocks";
							#clock-cells = <0x02>;
							phandle = <0x29>;
						};
					};

					service@7 {
						compatible = "qcom,q6asm";
						reg = <0x07>;
						qcom,protection-domain = "avs/audio\0msm/adsp/audio_pd";

						dais {
							compatible = "qcom,q6asm-dais";
							#address-cells = <0x01>;
							#size-cells = <0x00>;
							#sound-dai-cells = <0x01>;
							iommus = <0x30 0x1c1 0x00>;

							dai@0 {
								reg = <0x00>;
							};

							dai@1 {
								reg = <0x01>;
							};

							dai@2 {
								reg = <0x02>;
							};
						};
					};

					service@8 {
						compatible = "qcom,q6adm";
						reg = <0x08>;
						qcom,protection-domain = "avs/audio\0msm/adsp/audio_pd";

						routing {
							compatible = "qcom,q6adm-routing";
							#sound-dai-cells = <0x00>;
						};
					};
				};

				fastrpc {
					compatible = "qcom,fastrpc";
					qcom,glink-channels = "fastrpcglink-apps-dsp";
					label = "adsp";
					qcom,non-secure-domain;
					#address-cells = <0x01>;
					#size-cells = <0x00>;

					compute-cb@3 {
						compatible = "qcom,fastrpc-compute-cb";
						reg = <0x03>;
						iommus = <0x30 0x1c3 0x00>;
					};

					compute-cb@4 {
						compatible = "qcom,fastrpc-compute-cb";
						reg = <0x04>;
						iommus = <0x30 0x1c4 0x00>;
					};

					compute-cb@5 {
						compatible = "qcom,fastrpc-compute-cb";
						reg = <0x05>;
						iommus = <0x30 0x1c5 0x00>;
					};

					compute-cb@6 {
						compatible = "qcom,fastrpc-compute-cb";
						reg = <0x06>;
						iommus = <0x30 0x1c6 0x00>;
					};

					compute-cb@7 {
						compatible = "qcom,fastrpc-compute-cb";
						reg = <0x07>;
						iommus = <0x30 0x1c7 0x00>;
					};
				};
			};
		};

		remoteproc@b300000 {
			compatible = "qcom,sm6115-cdsp-pas";
			reg = <0x00 0xb300000 0x00 0x4040>;
			interrupts-extended = <0x01 0x00 0x109 0x01 0xa3 0x00 0x01 0xa3 0x01 0x01 0xa3 0x02 0x01 0xa3 0x03 0x01>;
			interrupt-names = "wdog\0fatal\0ready\0handover\0stop-ack";
			clocks = <0x2b 0x00>;
			clock-names = "xo";
			power-domains = <0x37 0x00>;
			memory-region = <0xa4>;
			qcom,smem-states = <0xa5 0x00>;
			qcom,smem-state-names = "stop";
			status = "okay";
			firmware-name = "qcom/sm6225/LENOVO/TB128FU/cdsp.mbn";

			glink-edge {
				interrupts = <0x00 0x105 0x01>;
				label = "cdsp";
				qcom,remote-pid = <0x05>;
				mboxes = <0x24 0x1c>;

				fastrpc {
					compatible = "qcom,fastrpc";
					qcom,glink-channels = "fastrpcglink-apps-dsp";
					label = "cdsp";
					qcom,non-secure-domain;
					#address-cells = <0x01>;
					#size-cells = <0x00>;

					compute-cb@1 {
						compatible = "qcom,fastrpc-compute-cb";
						reg = <0x01>;
						iommus = <0x30 0xc01 0x00>;
					};

					compute-cb@2 {
						compatible = "qcom,fastrpc-compute-cb";
						reg = <0x02>;
						iommus = <0x30 0xc02 0x00>;
					};

					compute-cb@3 {
						compatible = "qcom,fastrpc-compute-cb";
						reg = <0x03>;
						iommus = <0x30 0xc03 0x00>;
					};

					compute-cb@4 {
						compatible = "qcom,fastrpc-compute-cb";
						reg = <0x04>;
						iommus = <0x30 0xc04 0x00>;
					};

					compute-cb@5 {
						compatible = "qcom,fastrpc-compute-cb";
						reg = <0x05>;
						iommus = <0x30 0xc05 0x00>;
					};

					compute-cb@6 {
						compatible = "qcom,fastrpc-compute-cb";
						reg = <0x06>;
						iommus = <0x30 0xc06 0x00>;
					};
				};
			};
		};

		iommu@c600000 {
			compatible = "qcom,sm6115-smmu-500\0qcom,smmu-500\0arm,mmu-500";
			reg = <0x00 0xc600000 0x00 0x80000>;
			#iommu-cells = <0x02>;
			#global-interrupts = <0x01>;
			interrupts = <0x00 0x51 0x04 0x00 0x58 0x04 0x00 0x59 0x04 0x00 0x5a 0x04 0x00 0x5b 0x04 0x00 0x5c 0x04 0x00 0x5d 0x04 0x00 0x5e 0x04 0x00 0x5f 0x04 0x00 0x60 0x04 0x00 0x61 0x04 0x00 0x62 0x04 0x00 0x63 0x04 0x00 0x64 0x04 0x00 0x65 0x04 0x00 0x66 0x04 0x00 0x67 0x04 0x00 0x68 0x04 0x00 0x69 0x04 0x00 0x6a 0x04 0x00 0x6b 0x04 0x00 0x6c 0x04 0x00 0x6d 0x04 0x00 0x6e 0x04 0x00 0x6f 0x04 0x00 0x70 0x04 0x00 0x71 0x04 0x00 0x72 0x04 0x00 0x73 0x04 0x00 0x74 0x04 0x00 0x75 0x04 0x00 0x76 0x04 0x00 0x77 0x04 0x00 0x78 0x04 0x00 0x79 0x04 0x00 0x7a 0x04 0x00 0x7b 0x04 0x00 0x7c 0x04 0x00 0x7d 0x04 0x00 0x7e 0x04 0x00 0x7f 0x04 0x00 0x80 0x04 0x00 0x81 0x04 0x00 0x82 0x04 0x00 0x83 0x04 0x00 0x84 0x04 0x00 0x85 0x04 0x00 0x86 0x04 0x00 0x87 0x04 0x00 0x88 0x04 0x00 0x89 0x04 0x00 0x8a 0x04 0x00 0x8b 0x04 0x00 0x8c 0x04 0x00 0x8d 0x04 0x00 0x8e 0x04 0x00 0x8f 0x04 0x00 0x90 0x04 0x00 0x91 0x04 0x00 0x92 0x04 0x00 0x93 0x04 0x00 0x94 0x04 0x00 0x95 0x04 0x00 0x96 0x04 0x00 0x97 0x04>;
			phandle = <0x30>;
		};

		wifi@c800000 {
			compatible = "qcom,wcn3990-wifi";
			reg = <0x00 0xc800000 0x00 0x800000>;
			reg-names = "membase";
			memory-region = <0xa6>;
			interrupts = <0x00 0x166 0x04 0x00 0x167 0x04 0x00 0x168 0x04 0x00 0x169 0x04 0x00 0x16a 0x04 0x00 0x16b 0x04 0x00 0x16c 0x04 0x00 0x16d 0x04 0x00 0x16e 0x04 0x00 0x16f 0x04 0x00 0x170 0x04 0x00 0x171 0x04>;
			iommus = <0x30 0x1a0 0x01>;
			qcom,msa-fixed-perm;
			status = "okay";
			firmware-name = "lenovo-tb128fu";
			vdd-0.8-cx-mx-supply = <0xa7>;
			vdd-1.8-xo-supply = <0x59>;
			vdd-1.3-rfa-supply = <0xa8>;
			vdd-3.3-ch0-supply = <0xa9>;
			vdd-3.3-ch1-supply = <0xa9>;
		};

		watchdog@f017000 {
			compatible = "qcom,apss-wdt-sm6115\0qcom,kpss-wdt";
			reg = <0x00 0xf017000 0x00 0x1000>;
			clocks = <0x2c>;
			interrupts = <0x00 0x03 0x01>;
		};

		mailbox@f111000 {
			compatible = "qcom,sm6115-apcs-hmss-global\0qcom,msm8994-apcs-kpss-global";
			reg = <0x00 0xf111000 0x00 0x1000>;
			#mbox-cells = <0x01>;
			phandle = <0x24>;
		};

		timer@f120000 {
			compatible = "arm,armv7-timer-mem";
			reg = <0x00 0xf120000 0x00 0x1000>;
			#address-cells = <0x02>;
			#size-cells = <0x01>;
			ranges = <0x00 0x00 0x00 0x00 0x20000000>;
			clock-frequency = <0x124f800>;

			frame@f121000 {
				reg = <0x00 0xf121000 0x1000 0x00 0xf122000 0x1000>;
				frame-number = <0x00>;
				interrupts = <0x00 0x08 0x04 0x00 0x07 0x04>;
			};

			frame@f123000 {
				reg = <0x00 0xf123000 0x1000>;
				frame-number = <0x01>;
				interrupts = <0x00 0x09 0x04>;
				status = "disabled";
			};

			frame@f124000 {
				reg = <0x00 0xf124000 0x1000>;
				frame-number = <0x02>;
				interrupts = <0x00 0x0a 0x04>;
				status = "disabled";
			};

			frame@f125000 {
				reg = <0x00 0xf125000 0x1000>;
				frame-number = <0x03>;
				interrupts = <0x00 0x0b 0x04>;
				status = "disabled";
			};

			frame@f126000 {
				reg = <0x00 0xf126000 0x1000>;
				frame-number = <0x04>;
				interrupts = <0x00 0x0c 0x04>;
				status = "disabled";
			};

			frame@f127000 {
				reg = <0x00 0xf127000 0x1000>;
				frame-number = <0x05>;
				interrupts = <0x00 0x0d 0x04>;
				status = "disabled";
			};

			frame@f128000 {
				reg = <0x00 0xf128000 0x1000>;
				frame-number = <0x06>;
				interrupts = <0x00 0x0e 0x04>;
				status = "disabled";
			};
		};

		interrupt-controller@f200000 {
			compatible = "arm,gic-v3";
			reg = <0x00 0xf200000 0x00 0x10000 0x00 0xf300000 0x00 0x100000>;
			#interrupt-cells = <0x03>;
			interrupt-controller;
			interrupt-parent = <0x01>;
			#redistributor-regions = <0x01>;
			redistributor-stride = <0x00 0x20000>;
			interrupts = <0x01 0x09 0x04>;
			phandle = <0x01>;
		};

		cpufreq@f521000 {
			compatible = "qcom,sm6115-cpufreq-hw\0qcom,cpufreq-hw";
			reg = <0x00 0xf521000 0x00 0x1000 0x00 0xf523000 0x00 0x1000>;
			reg-names = "freq-domain0\0freq-domain1";
			clocks = <0x2b 0x00 0x02 0x00>;
			clock-names = "xo\0alternate";
			#freq-domain-cells = <0x01>;
			#clock-cells = <0x01>;
			phandle = <0x03>;
		};
		disp_rdump_region@5c000000 {
			label = "disp_rdump_region";
			reg = <0x00 0x5c000000 0x00 0xf00000>;
		};

	};

	thermal-zones {

		mapss-thermal {
			thermal-sensors = <0xaa 0x00>;

			trips {

				trip-point0 {
					temperature = <0x1c138>;
					hysteresis = <0x1388>;
					type = "passive";
				};

				trip-point1 {
					temperature = <0x1e848>;
					hysteresis = <0x3e8>;
					type = "passive";
				};
			};
		};

		cdsp-hvx-thermal {
			thermal-sensors = <0xaa 0x01>;

			trips {

				trip-point0 {
					temperature = <0x1c138>;
					hysteresis = <0x1388>;
					type = "passive";
				};

				trip-point1 {
					temperature = <0x1e848>;
					hysteresis = <0x3e8>;
					type = "passive";
				};
			};
		};

		wlan-thermal {
			thermal-sensors = <0xaa 0x02>;

			trips {

				trip-point0 {
					temperature = <0x1c138>;
					hysteresis = <0x1388>;
					type = "passive";
				};

				trip-point1 {
					temperature = <0x1e848>;
					hysteresis = <0x3e8>;
					type = "passive";
				};
			};
		};

		camera-thermal {
			thermal-sensors = <0xaa 0x03>;

			trips {

				trip-point0 {
					temperature = <0x1c138>;
					hysteresis = <0x1388>;
					type = "passive";
				};

				trip-point1 {
					temperature = <0x1e848>;
					hysteresis = <0x3e8>;
					type = "passive";
				};
			};
		};

		video-thermal {
			thermal-sensors = <0xaa 0x04>;

			trips {

				trip-point0 {
					temperature = <0x1c138>;
					hysteresis = <0x1388>;
					type = "passive";
				};

				trip-point1 {
					temperature = <0x1e848>;
					hysteresis = <0x3e8>;
					type = "passive";
				};
			};
		};

		modem1-thermal {
			thermal-sensors = <0xaa 0x05>;

			trips {

				trip-point0 {
					temperature = <0x1c138>;
					hysteresis = <0x1388>;
					type = "passive";
				};

				trip-point1 {
					temperature = <0x1e848>;
					hysteresis = <0x3e8>;
					type = "passive";
				};
			};
		};

		cpu4-thermal {
			thermal-sensors = <0xaa 0x06>;

			trips {

				trip-point0 {
					temperature = <0x15f90>;
					hysteresis = <0x7d0>;
					type = "passive";
				};

				trip-point1 {
					temperature = <0x17318>;
					hysteresis = <0x7d0>;
					type = "passive";
				};

				cpu-crit {
					temperature = <0x1adb0>;
					hysteresis = <0x3e8>;
					type = "critical";
				};
			};
		};

		cpu5-thermal {
			thermal-sensors = <0xaa 0x07>;

			trips {

				trip-point0 {
					temperature = <0x15f90>;
					hysteresis = <0x7d0>;
					type = "passive";
				};

				trip-point1 {
					temperature = <0x17318>;
					hysteresis = <0x7d0>;
					type = "passive";
				};

				cpu-crit {
					temperature = <0x1adb0>;
					hysteresis = <0x3e8>;
					type = "critical";
				};
			};
		};

		cpu6-thermal {
			thermal-sensors = <0xaa 0x08>;

			trips {

				trip-point0 {
					temperature = <0x15f90>;
					hysteresis = <0x7d0>;
					type = "passive";
				};

				trip-point1 {
					temperature = <0x17318>;
					hysteresis = <0x7d0>;
					type = "passive";
				};

				cpu-crit {
					temperature = <0x1adb0>;
					hysteresis = <0x3e8>;
					type = "critical";
				};
			};
		};

		cpu7-thermal {
			thermal-sensors = <0xaa 0x09>;

			trips {

				trip-point0 {
					temperature = <0x15f90>;
					hysteresis = <0x7d0>;
					type = "passive";
				};

				trip-point1 {
					temperature = <0x17318>;
					hysteresis = <0x7d0>;
					type = "passive";
				};

				cpu-crit {
					temperature = <0x1adb0>;
					hysteresis = <0x3e8>;
					type = "critical";
				};
			};
		};

		cpu45-thermal {
			thermal-sensors = <0xaa 0x0a>;

			trips {

				trip-point0 {
					temperature = <0x15f90>;
					hysteresis = <0x7d0>;
					type = "passive";
				};

				trip-point1 {
					temperature = <0x17318>;
					hysteresis = <0x7d0>;
					type = "passive";
				};

				cpu-crit {
					temperature = <0x1adb0>;
					hysteresis = <0x3e8>;
					type = "critical";
				};
			};
		};

		cpu67-thermal {
			thermal-sensors = <0xaa 0x0b>;

			trips {

				trip-point0 {
					temperature = <0x15f90>;
					hysteresis = <0x7d0>;
					type = "passive";
				};

				trip-point1 {
					temperature = <0x17318>;
					hysteresis = <0x7d0>;
					type = "passive";
				};

				cpu-crit {
					temperature = <0x1adb0>;
					hysteresis = <0x3e8>;
					type = "critical";
				};
			};
		};

		cpu0123-thermal {
			thermal-sensors = <0xaa 0x0c>;

			trips {

				trip-point0 {
					temperature = <0x15f90>;
					hysteresis = <0x7d0>;
					type = "passive";
				};

				trip-point1 {
					temperature = <0x17318>;
					hysteresis = <0x7d0>;
					type = "passive";
				};

				cpu-crit {
					temperature = <0x1adb0>;
					hysteresis = <0x3e8>;
					type = "critical";
				};
			};
		};

		modem0-thermal {
			thermal-sensors = <0xaa 0x0d>;

			trips {

				trip-point0 {
					temperature = <0x1c138>;
					hysteresis = <0x1388>;
					type = "passive";
				};

				trip-point1 {
					temperature = <0x1e848>;
					hysteresis = <0x3e8>;
					type = "passive";
				};
			};
		};

		display-thermal {
			thermal-sensors = <0xaa 0x0e>;

			trips {

				trip-point0 {
					temperature = <0x1c138>;
					hysteresis = <0x1388>;
					type = "passive";
				};

				trip-point1 {
					temperature = <0x1e848>;
					hysteresis = <0x3e8>;
					type = "passive";
				};
			};
		};

		gpu-thermal {
			polling-delay-passive = <0xfa>;
			thermal-sensors = <0xaa 0x0f>;

			cooling-maps {

				map0 {
					trip = <0xab>;
					cooling-device = <0xac 0xffffffff 0xffffffff>;
				};
			};

			trips {

				trip-point0 {
					temperature = <0x14c08>;
					hysteresis = <0x3e8>;
					type = "passive";
					phandle = <0xab>;
				};

				trip-point1 {
					temperature = <0x1adb0>;
					hysteresis = <0x3e8>;
					type = "critical";
				};
			};
		};

		pm6125-thermal {
			polling-delay-passive = <0x64>;
			thermal-sensors = <0xad>;

			trips {

				trip0 {
					temperature = <0x17318>;
					hysteresis = <0x00>;
					type = "passive";
				};

				trip1 {
					temperature = <0x1c138>;
					hysteresis = <0x00>;
					type = "hot";
				};

				trip2 {
					temperature = <0x23668>;
					hysteresis = <0x00>;
					type = "critical";
				};
			};
		};
	};

	timer {
		compatible = "arm,armv8-timer";
		interrupts = <0x01 0x01 0xf08 0x01 0x02 0xf08 0x01 0x03 0xf08 0x01 0x00 0xf08>;
	};

	mem-offline {
		compatible = "qcom,mem-offline";
		offline-sizes = <0x01 0x40000000 0x00 0x40000000 0x01 0xc0000000 0x00 0x80000000 0x02 0xc0000000 0x01 0x40000000>;
		granule = <0x200>;
	};

	ddr-regions {
	};

	aliases {
		mmc0 = "/soc/mmc@4784000";
		serial0 = "/soc/geniqup@4ac0000/serial@4a90000";
		serial1 = "/soc/geniqup@4ac0000/serial@4a8c000";
	};

	battery {
		compatible = "simple-battery";
		charge-full-design-microamp-hours = <0x15d1f0>;
		energy-full-design-microwatt-hours = <0x50b810>;
		voltage-min-design-microvolt = <0x30d400>;
		phandle = <0x4f>;
	};

	gpio-keys {
		compatible = "gpio-keys";
		pinctrl-names = "default";
		pinctrl-0 = <0xae>;

		key-volume-up {
			label = "Volume Up";
			linux,code = <0x73>;
			gpios = <0x36 0x05 0x01>;
			debounce-interval = <0x0f>;
			linux,can-disable;
			wakeup-source;
		};
	};

	regulator-0 {
		regulator-always-on;
		regulator-boot-on;
		compatible = "regulator-fixed";
		regulator-name = "vbus_p1";
		regulator-min-microvolt = <0x4c4b40>;
		regulator-max-microvolt = <0x4c4b40>;
		gpio = <0x28 0x48 0x00>;
		enable-active-high;
		status = "okay";
	};
	abl-stubs {

		CPU0: CPU0 {
			phandle = <0x1ae>;
		};
		CPU4: CPU4 {
			phandle = <0x1af>;
		};
		L11A: L11A {
			phandle = <0x1b0>;
		};
		L14A: L14A {
			phandle = <0x1b1>;
		};
		L15A: L15A {
			phandle = <0x1b2>;
		};
		L18A: L18A {
			phandle = <0x1b3>;
		};
		L19A: L19A {
			phandle = <0x1b4>;
		};
		L1A: L1A {
			phandle = <0x1b5>;
		};
		L20A: L20A {
			phandle = <0x1b6>;
		};
		L21A: L21A {
			phandle = <0x1b7>;
		};
		L22A: L22A {
			phandle = <0x1b8>;
		};
		L24A: L24A {
			phandle = <0x1b9>;
		};
		L4A: L4A {
			phandle = <0x1ba>;
		};
		L5A: L5A {
			phandle = <0x1bb>;
		};
		L7A: L7A {
			phandle = <0x1bc>;
		};
		L7P: L7P {
			phandle = <0x1bd>;
		};
		L9A: L9A {
			phandle = <0x1be>;
		};
		adsp_loader: adsp_loader {
			phandle = <0x1bf>;
		};
		adsp_variant: adsp_variant {
			phandle = <0x1c0>;
		};
		apps_smmu: apps_smmu {
			phandle = <0x1c1>;
		};
		audio_gpr: audio_gpr {
			phandle = <0x1c2>;
		};
		bimc: bimc {
			phandle = <0x1c3>;
		};
		bolero_cdc: bolero_cdc {
			phandle = <0x1c4>;
		};
		cam_cci0: cam_cci0 {
			phandle = <0x1c5>;
		};
		cam_sensor_front0_reset_active: cam_sensor_front0_reset_active {
			phandle = <0x1c6>;
		};
		cam_sensor_front0_reset_suspend: cam_sensor_front0_reset_suspend {
			phandle = <0x1c7>;
		};
		cam_sensor_mclk0_active: cam_sensor_mclk0_active {
			phandle = <0x1c8>;
		};
		cam_sensor_mclk0_suspend: cam_sensor_mclk0_suspend {
			phandle = <0x1c9>;
		};
		cam_sensor_mclk1_active: cam_sensor_mclk1_active {
			phandle = <0x1ca>;
		};
		cam_sensor_mclk1_suspend: cam_sensor_mclk1_suspend {
			phandle = <0x1cb>;
		};
		cam_sensor_rear0_reset_active: cam_sensor_rear0_reset_active {
			phandle = <0x1cc>;
		};
		cam_sensor_rear0_reset_suspend: cam_sensor_rear0_reset_suspend {
			phandle = <0x1cd>;
		};
		camera_therm_default: camera_therm_default {
			phandle = <0x1ce>;
		};
		config_noc: config_noc {
			phandle = <0x1cf>;
		};
		cpu1_pause: cpu1_pause {
			phandle = <0x1d0>;
		};
		cpu2_pause: cpu2_pause {
			phandle = <0x1d1>;
		};
		cpu3_pause: cpu3_pause {
			phandle = <0x1d2>;
		};
		cpu4_pause: cpu4_pause {
			phandle = <0x1d3>;
		};
		cpu5_pause: cpu5_pause {
			phandle = <0x1d4>;
		};
		cpu6_pause: cpu6_pause {
			phandle = <0x1d5>;
		};
		cpu7_pause: cpu7_pause {
			phandle = <0x1d6>;
		};
		dispcc: dispcc {
			phandle = <0x1d7>;
		};
		emmc_therm_default: emmc_therm_default {
			phandle = <0x1d8>;
		};
		eud: eud {
			phandle = <0x1d9>;
		};
		gcc: gcc {
			phandle = <0x1da>;
		};
		gcc_camss_top_gdsc: gcc_camss_top_gdsc {
			phandle = <0x1db>;
		};
		gcc_ufs_phy_gdsc: gcc_ufs_phy_gdsc {
			phandle = <0x1dc>;
		};
		lpass_audio_hw_vote: lpass_audio_hw_vote {
			phandle = <0x1dd>;
		};
		lpi_i2s1_sck_active: lpi_i2s1_sck_active {
			phandle = <0x1de>;
		};
		lpi_i2s1_sck_sleep: lpi_i2s1_sck_sleep {
			phandle = <0x1df>;
		};
		lpi_i2s1_sd0_active: lpi_i2s1_sd0_active {
			phandle = <0x1e0>;
		};
		lpi_i2s1_sd0_sleep: lpi_i2s1_sd0_sleep {
			phandle = <0x1e1>;
		};
		lpi_i2s1_sd1_active: lpi_i2s1_sd1_active {
			phandle = <0x1e2>;
		};
		lpi_i2s1_sd1_sleep: lpi_i2s1_sd1_sleep {
			phandle = <0x1e3>;
		};
		lpi_i2s1_ws_active: lpi_i2s1_ws_active {
			phandle = <0x1e4>;
		};
		lpi_i2s1_ws_sleep: lpi_i2s1_ws_sleep {
			phandle = <0x1e5>;
		};
		lpi_i2s2_sck_active: lpi_i2s2_sck_active {
			phandle = <0x1e6>;
		};
		lpi_i2s2_sck_sleep: lpi_i2s2_sck_sleep {
			phandle = <0x1e7>;
		};
		lpi_i2s2_sd0_active: lpi_i2s2_sd0_active {
			phandle = <0x1e8>;
		};
		lpi_i2s2_sd0_sleep: lpi_i2s2_sd0_sleep {
			phandle = <0x1e9>;
		};
		lpi_i2s2_sd1_active: lpi_i2s2_sd1_active {
			phandle = <0x1ea>;
		};
		lpi_i2s2_sd1_sleep: lpi_i2s2_sd1_sleep {
			phandle = <0x1eb>;
		};
		lpi_i2s2_ws_active: lpi_i2s2_ws_active {
			phandle = <0x1ec>;
		};
		lpi_i2s2_ws_sleep: lpi_i2s2_ws_sleep {
			phandle = <0x1ed>;
		};
		lpi_tlmm: lpi_tlmm {
			phandle = <0x1ee>;
		};
		mdss_core_gdsc: mdss_core_gdsc {
			phandle = <0x1ef>;
		};
		mmrt_virt: mmrt_virt {
			phandle = <0x1f0>;
		};
		nfc_clk_req_active: nfc_clk_req_active {
			phandle = <0x1f1>;
		};
		nfc_clk_req_suspend: nfc_clk_req_suspend {
			phandle = <0x1f2>;
		};
		nfc_enable_active: nfc_enable_active {
			phandle = <0x1f3>;
		};
		nfc_enable_suspend: nfc_enable_suspend {
			phandle = <0x1f4>;
		};
		nfc_int_active: nfc_int_active {
			phandle = <0x1f5>;
		};
		nfc_int_suspend: nfc_int_suspend {
			phandle = <0x1f6>;
		};
		pm6125_adc_tm: pm6125_adc_tm {
			phandle = <0x1f7>;
		};
		pm6125_gpios: pm6125_gpios {
			phandle = <0x1f8>;
		};
		pm6125_pwm: pm6125_pwm {
			phandle = <0x1f9>;
		};
		pm6125_trip0: pm6125_trip0 {
			phandle = <0x1fa>;
		};
		pm6125_trip1: pm6125_trip1 {
			phandle = <0x1fb>;
		};
		pm6125_vadc: pm6125_vadc {
			phandle = <0x1fc>;
		};
		pm8008_8: pm8008_8 {
			phandle = <0x1fd>;
		};
		pm8008_9: pm8008_9 {
			phandle = <0x1fe>;
		};
		qupv3_se0_spi: qupv3_se0_spi {
			phandle = <0x1ff>;
		};
		qupv3_se1_i2c: qupv3_se1_i2c {
			phandle = <0x200>;
		};
		qupv3_se2_i2c: qupv3_se2_i2c {
			phandle = <0x201>;
		};
		qupv3_se4_2uart: qupv3_se4_2uart {
			phandle = <0x202>;
		};
		qupv3_se5_i2c: qupv3_se5_i2c {
			phandle = <0x203>;
		};
		refgen: refgen {
			phandle = <0x204>;
		};
		reserved_memory: reserved_memory {
			phandle = <0x205>;
		};
		rpmcc: rpmcc {
			phandle = <0x206>;
		};
		rx_swr_gpios: rx_swr_gpios {
			phandle = <0x207>;
		};
		sdc1_off: sdc1_off {
			phandle = <0x208>;
		};
		sdc1_on: sdc1_on {
			phandle = <0x209>;
		};
		sdc2_off: sdc2_off {
			phandle = <0x20a>;
		};
		sdc2_on: sdc2_on {
			phandle = <0x20b>;
		};
		sde_dsi_active: sde_dsi_active {
			phandle = <0x20c>;
		};
		sde_dsi_suspend: sde_dsi_suspend {
			phandle = <0x20d>;
		};
		sde_te_active: sde_te_active {
			phandle = <0x20e>;
		};
		sde_te_suspend: sde_te_suspend {
			phandle = <0x20f>;
		};
		sdhc_1: sdhc_1 {
			phandle = <0x210>;
		};
		sdhc_2: sdhc_2 {
			phandle = <0x211>;
		};
		soc: soc {
			phandle = <0x212>;
		};
		spf_core_platform: spf_core_platform {
			phandle = <0x213>;
		};
		spmi_bus: spmi_bus {
			phandle = <0x214>;
		};
		stub_codec: stub_codec {
			phandle = <0x215>;
		};
		thermal_zones: thermal_zones {
			phandle = <0x216>;
		};
		tlmm: tlmm {
			phandle = <0x217>;
		};
		ts_int_active: ts_int_active {
			phandle = <0x218>;
		};
		ts_int_suspend: ts_int_suspend {
			phandle = <0x219>;
		};
		ts_release: ts_release {
			phandle = <0x21a>;
		};
		ts_reset_active: ts_reset_active {
			phandle = <0x21b>;
		};
		ts_reset_suspend: ts_reset_suspend {
			phandle = <0x21c>;
		};
		ufshc_mem: ufshc_mem {
			phandle = <0x21d>;
		};
		ufsphy_mem: ufsphy_mem {
			phandle = <0x21e>;
		};
		usb0: usb0 {
			phandle = <0x21f>;
		};
		usb2_phy0: usb2_phy0 {
			phandle = <0x220>;
		};
		usb_qmp_dp_phy: usb_qmp_dp_phy {
			phandle = <0x221>;
		};
		va_swr_gpios: va_swr_gpios {
			phandle = <0x222>;
		};
		wcd937x_reset_active: wcd937x_reset_active {
			phandle = <0x223>;
		};
		wcd937x_reset_sleep: wcd937x_reset_sleep {
			phandle = <0x224>;
		};
		wsa881x_analog_clk_gpio: wsa881x_analog_clk_gpio {
			phandle = <0x225>;
		};
	};
};
